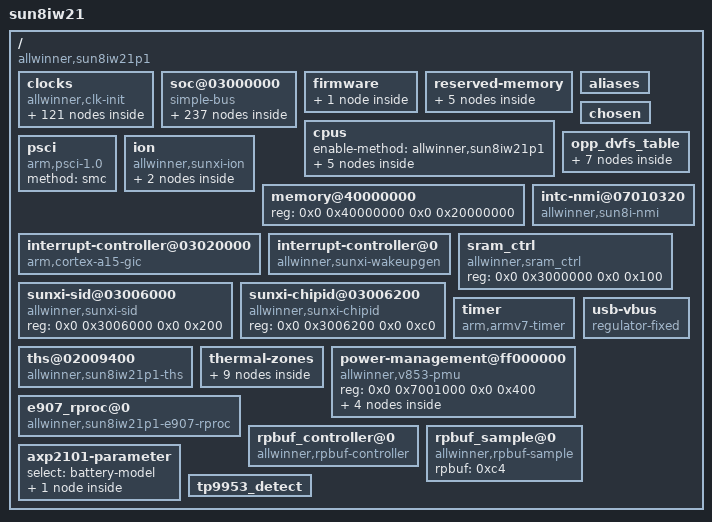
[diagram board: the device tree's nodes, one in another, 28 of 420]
/dts-v1/;

/ {
	model = "sun8iw21";
	compatible = "allwinner,sun8iw21p1";
	interrupt-parent = <0x1>;
	#address-cells = <0x2>;
	#size-cells = <0x2>;

	clocks {
		compatible = "allwinner,clk-init";
		device_type = "clocks";
		#address-cells = <0x2>;
		#size-cells = <0x2>;
		ranges;
		reg = <0x0 0x2001000 0x0 0x1000 0x0 0x7010000 0x0 0x400 0x0 0x7090000 0x0 0x400>;

		ext_losc {
			#clock-cells = <0x0>;
			compatible = "allwinner,fixed-clock";
			clock-frequency = <0x8000>;
			clock-output-names = "ext_losc";
		};

		iosc {
			#clock-cells = <0x0>;
			compatible = "allwinner,fixed-clock";
			clock-frequency = <0xf42400>;
			clock-output-names = "iosc";
			linux,phandle = <0x3>;
			phandle = <0x3>;
		};

		hosc {
			#clock-cells = <0x0>;
			compatible = "allwinner,fixed-clock";
			clock-frequency = <0x16e3600>;
			clock-output-names = "hosc";
			linux,phandle = <0xc>;
			phandle = <0xc>;
		};

		hoscdiv32k {
			#clock-cells = <0x0>;
			compatible = "allwinner,fixed-clock";
			clock-frequency = <0x8000>;
			clock-output-names = "hoscdiv32k";
		};

		osc48m {
			#clock-cells = <0x0>;
			compatible = "allwinner,fixed-clock";
			clock-frequency = <0x2dc6c00>;
			clock-output-names = "osc48m";
			linux,phandle = <0xd>;
			phandle = <0xd>;
		};

		pll_cpu {
			#clock-cells = <0x0>;
			compatible = "allwinner,pll-clock";
			lock-mode = "new";
			clock-output-names = "pll_cpu";
			linux,phandle = <0xb3>;
			phandle = <0xb3>;
		};

		pll_ddr0 {
			#clock-cells = <0x0>;
			compatible = "allwinner,pll-clock";
			lock-mode = "new";
			clock-output-names = "pll_ddr0";
		};

		pll_periph0x2 {
			#clock-cells = <0x0>;
			compatible = "allwinner,pll-clock";
			assigned-clock-rates = <0x47868c00>;
			lock-mode = "new";
			clock-output-names = "pll_periph0x2";
			linux,phandle = <0x4>;
			phandle = <0x4>;
		};

		pll_periph0800m {
			#clock-cells = <0x0>;
			compatible = "allwinner,pll-clock";
			assigned-clock-rates = <0x2faf0800>;
			lock-mode = "new";
			clock-output-names = "pll_periph0800m";
		};

		pll_periph0480m {
			#clock-cells = <0x0>;
			compatible = "allwinner,pll-clock";
			lock-mode = "new";
			clock-output-names = "pll_periph0480m";
			linux,phandle = <0x7>;
			phandle = <0x7>;
		};

		pll_video0x4 {
			#clock-cells = <0x0>;
			compatible = "allwinner,pll-clock";
			lock-mode = "new";
			clock-output-names = "pll_video0x4";
			linux,phandle = <0xb>;
			phandle = <0xb>;
		};

		pll_csix4 {
			#clock-cells = <0x0>;
			compatible = "allwinner,pll-clock";
			assigned-clock-rates = <0x46cf7100>;
			lock-mode = "new";
			clock-output-names = "pll_csix4";
			linux,phandle = <0x9b>;
			phandle = <0x9b>;
		};

		pll_audio_div2 {
			#clock-cells = <0x0>;
			compatible = "allwinner,pll-clock";
			assigned-clock-rates = <0x5b8d8000>;
			lock-mode = "new";
			clock-output-names = "pll_audio_div2";
		};

		pll_audio_div5 {
			#clock-cells = <0x0>;
			compatible = "allwinner,pll-clock";
			assigned-clock-rates = <0x249f0000>;
			lock-mode = "new";
			clock-output-names = "pll_audio_div5";
		};

		pll_npux4 {
			#clock-cells = <0x0>;
			compatible = "allwinner,pll-clock";
			lock-mode = "new";
			clock-output-names = "pll_npux4";
			assigned-clock-rates = <0x52f83c00>;
			assigned-clocks = <0x2>;
			linux,phandle = <0x2>;
			phandle = <0x2>;
		};

		iosc32k {
			#clock-cells = <0x0>;
			compatible = "allwinner,fixed-factor-clock";
			clocks = <0x3>;
			clock-mult = <0x1>;
			clock-div = <0x1f4>;
			clock-output-names = "iosc32k";
		};

		pll_periph0600m {
			#clock-cells = <0x0>;
			compatible = "allwinner,fixed-factor-clock";
			clocks = <0x4>;
			clock-mult = <0x1>;
			clock-div = <0x2>;
			clock-output-names = "pll_periph0600m";
			linux,phandle = <0x5>;
			phandle = <0x5>;
		};

		pll_periph0400m {
			#clock-cells = <0x0>;
			compatible = "allwinner,fixed-factor-clock";
			clocks = <0x4>;
			clock-mult = <0x1>;
			clock-div = <0x3>;
			clock-output-names = "pll_periph0400m";
			linux,phandle = <0x6>;
			phandle = <0x6>;
		};

		pll_periph0300m {
			#clock-cells = <0x0>;
			compatible = "allwinner,fixed-factor-clock";
			clocks = <0x5>;
			clock-mult = <0x1>;
			clock-div = <0x2>;
			clock-output-names = "pll_periph0300m";
			linux,phandle = <0x8>;
			phandle = <0x8>;
		};

		pll_periph0200m {
			#clock-cells = <0x0>;
			compatible = "allwinner,fixed-factor-clock";
			clocks = <0x6>;
			clock-mult = <0x1>;
			clock-div = <0x2>;
			clock-output-names = "pll_periph0200m";
		};

		pll_periph0160m {
			#clock-cells = <0x0>;
			compatible = "allwinner,fixed-factor-clock";
			clocks = <0x7>;
			clock-mult = <0x1>;
			clock-div = <0x3>;
			clock-output-names = "pll_periph0160m";
			linux,phandle = <0xa>;
			phandle = <0xa>;
		};

		pll_periph0150m {
			#clock-cells = <0x0>;
			compatible = "allwinner,fixed-factor-clock";
			clocks = <0x8>;
			clock-mult = <0x1>;
			clock-div = <0x2>;
			clock-output-names = "pll_periph0150m";
			linux,phandle = <0x9>;
			phandle = <0x9>;
		};

		pll_periph0150m_div6 {
			#clock-cells = <0x0>;
			compatible = "allwinner,fixed-factor-clock";
			clocks = <0x9>;
			clock-mult = <0x1>;
			clock-div = <0x6>;
			clock-output-names = "pll_periph0150m_div6";
		};

		pll_periph0160m_div10 {
			#clock-cells = <0x0>;
			compatible = "allwinner,fixed-factor-clock";
			clocks = <0xa>;
			clock-mult = <0x1>;
			clock-div = <0xa>;
			clock-output-names = "pll_periph0160m_div10";
		};

		pll_video0x2 {
			#clock-cells = <0x0>;
			compatible = "allwinner,fixed-factor-clock";
			clocks = <0xb>;
			clock-mult = <0x1>;
			clock-div = <0x2>;
			clock-output-names = "pll_video0x2";
		};

		pll_video0 {
			#clock-cells = <0x0>;
			compatible = "allwinner,fixed-factor-clock";
			clocks = <0xb>;
			clock-mult = <0x1>;
			clock-div = <0x4>;
			clock-output-names = "pll_video0";
			linux,phandle = <0x28>;
			phandle = <0x28>;
		};

		pll_npux2 {
			#clock-cells = <0x0>;
			compatible = "allwinner,fixed-factor-clock";
			clocks = <0x2>;
			clock-mult = <0x1>;
			clock-div = <0x2>;
			clock-output-names = "pll_npux2";
		};

		pll_npu {
			#clock-cells = <0x0>;
			compatible = "allwinner,fixed-factor-clock";
			clocks = <0x2>;
			clock-mult = <0x1>;
			clock-div = <0x4>;
			clock-output-names = "pll_npu";
		};

		hoscd2 {
			#clock-cells = <0x0>;
			compatible = "allwinner,fixed-factor-clock";
			clocks = <0xc>;
			clock-mult = <0x1>;
			clock-div = <0x2>;
			clock-output-names = "hoscd2";
		};

		osc48md4 {
			#clock-cells = <0x0>;
			compatible = "allwinner,fixed-factor-clock";
			clocks = <0xd>;
			clock-mult = <0x1>;
			clock-div = <0x4>;
			clock-output-names = "osc48md4";
		};

		sdramd4 {
			#clock-cells = <0x0>;
			compatible = "allwinner,fixed-factor-clock";
			clocks = <0xe>;
			clock-mult = <0x1>;
			clock-div = <0x4>;
			clock-output-names = "sdramd4";
		};

		cpu {
			#clock-cells = <0x0>;
			compatible = "allwinner,cpu-clock";
			clock-output-names = "cpu";
		};

		axi {
			#clock-cells = <0x0>;
			compatible = "allwinner,periph-clock";
			clock-output-names = "axi";
		};

		cpuapb {
			#clock-cells = <0x0>;
			compatible = "allwinner,periph-clock";
			clock-output-names = "cpuapb";
		};

		ahb {
			#clock-cells = <0x0>;
			compatible = "allwinner,periph-clock";
			clock-output-names = "ahb";
		};

		apb0 {
			#clock-cells = <0x0>;
			compatible = "allwinner,periph-clock";
			clock-output-names = "apb0";
			linux,phandle = <0x14>;
			phandle = <0x14>;
		};

		apb1 {
			#clock-cells = <0x0>;
			compatible = "allwinner,periph-clock";
			clock-output-names = "apb1";
		};

		de {
			#clock-cells = <0x0>;
			compatible = "allwinner,periph-clock";
			assigned-clock-rates = <0x11e1a300>;
			clock-output-names = "de";
			assigned-clock-parents = <0x8>;
			assigned-clocks = <0xf>;
			linux,phandle = <0xf>;
			phandle = <0xf>;
		};

		g2d {
			#clock-cells = <0x0>;
			compatible = "allwinner,periph-clock";
			assigned-clock-rates = <0x11e1a300>;
			clock-output-names = "g2d";
			assigned-clock-parents = <0x8>;
			assigned-clocks = <0x10>;
			linux,phandle = <0x10>;
			phandle = <0x10>;
		};

		ce {
			#clock-cells = <0x0>;
			compatible = "allwinner,periph-clock";
			clock-output-names = "ce";
			linux,phandle = <0x2b>;
			phandle = <0x2b>;
		};

		ve {
			#clock-cells = <0x0>;
			compatible = "allwinner,periph-clock";
			clock-output-names = "ve";
			linux,phandle = <0x29>;
			phandle = <0x29>;
		};

		npu {
			#clock-cells = <0x0>;
			compatible = "allwinner,periph-clock";
			clock-output-names = "npu";
			assigned-clock-parents = <0x2>;
			assigned-clock-rates = <0x14be0f00>;
			assigned-clocks = <0x11>;
			linux,phandle = <0x11>;
			phandle = <0x11>;
		};

		dma {
			#clock-cells = <0x0>;
			compatible = "allwinner,periph-clock";
			clock-output-names = "dma";
		};

		msgbox0 {
			#clock-cells = <0x0>;
			compatible = "allwinner,periph-clock";
			clock-output-names = "msgbox0";
			linux,phandle = <0x3a>;
			phandle = <0x3a>;
		};

		msgbox1 {
			#clock-cells = <0x0>;
			compatible = "allwinner,periph-clock";
			clock-output-names = "msgbox1";
		};

		spinlock {
			#clock-cells = <0x0>;
			compatible = "allwinner,periph-clock";
			clock-output-names = "spinlock";
			linux,phandle = <0x16>;
			phandle = <0x16>;
		};

		hstimer {
			#clock-cells = <0x0>;
			compatible = "allwinner,periph-clock";
			clock-output-names = "hstimer";
		};

		avs {
			#clock-cells = <0x0>;
			compatible = "allwinner,periph-clock";
			clock-output-names = "avs";
		};

		dbgsys {
			#clock-cells = <0x0>;
			compatible = "allwinner,periph-clock";
			clock-output-names = "dbgsys";
		};

		pwm {
			#clock-cells = <0x0>;
			compatible = "allwinner,periph-clock";
			clock-output-names = "pwm";
			linux,phandle = <0x57>;
			phandle = <0x57>;
		};

		iommu {
			#clock-cells = <0x0>;
			compatible = "allwinner,periph-clock";
			clock-output-names = "iommu";
			linux,phandle = <0x2a>;
			phandle = <0x2a>;
		};

		sdram {
			#clock-cells = <0x0>;
			compatible = "allwinner,periph-clock";
			clock-output-names = "sdram";
			linux,phandle = <0xe>;
			phandle = <0xe>;
		};

		sdmmc0_mod {
			#clock-cells = <0x0>;
			compatible = "allwinner,periph-clock";
			clock-output-names = "sdmmc0_mod";
			linux,phandle = <0x6e>;
			phandle = <0x6e>;
		};

		sdmmc0_bus {
			#clock-cells = <0x0>;
			compatible = "allwinner,periph-clock";
			clock-output-names = "sdmmc0_bus";
			linux,phandle = <0x6f>;
			phandle = <0x6f>;
		};

		sdmmc0_rst {
			#clock-cells = <0x0>;
			compatible = "allwinner,periph-clock";
			clock-output-names = "sdmmc0_rst";
			linux,phandle = <0x70>;
			phandle = <0x70>;
		};

		sdmmc1_mod {
			#clock-cells = <0x0>;
			compatible = "allwinner,periph-clock";
			clock-output-names = "sdmmc1_mod";
			linux,phandle = <0x74>;
			phandle = <0x74>;
		};

		sdmmc1_bus {
			#clock-cells = <0x0>;
			compatible = "allwinner,periph-clock";
			clock-output-names = "sdmmc1_bus";
			linux,phandle = <0x75>;
			phandle = <0x75>;
		};

		sdmmc1_rst {
			#clock-cells = <0x0>;
			compatible = "allwinner,periph-clock";
			clock-output-names = "sdmmc1_rst";
			linux,phandle = <0x76>;
			phandle = <0x76>;
		};

		sdmmc2_mod {
			#clock-cells = <0x0>;
			compatible = "allwinner,periph-clock";
			clock-output-names = "sdmmc2_mod";
			linux,phandle = <0x68>;
			phandle = <0x68>;
		};

		sdmmc2_bus {
			#clock-cells = <0x0>;
			compatible = "allwinner,periph-clock";
			clock-output-names = "sdmmc2_bus";
			linux,phandle = <0x69>;
			phandle = <0x69>;
		};

		sdmmc2_rst {
			#clock-cells = <0x0>;
			compatible = "allwinner,periph-clock";
			clock-output-names = "sdmmc2_rst";
			linux,phandle = <0x6a>;
			phandle = <0x6a>;
		};

		uart0 {
			#clock-cells = <0x0>;
			compatible = "allwinner,periph-clock";
			clock-output-names = "uart0";
			linux,phandle = <0x17>;
			phandle = <0x17>;
		};

		uart1 {
			#clock-cells = <0x0>;
			compatible = "allwinner,periph-clock";
			clock-output-names = "uart1";
			linux,phandle = <0x1b>;
			phandle = <0x1b>;
		};

		uart2 {
			#clock-cells = <0x0>;
			compatible = "allwinner,periph-clock";
			clock-output-names = "uart2";
			linux,phandle = <0x1e>;
			phandle = <0x1e>;
		};

		uart3 {
			#clock-cells = <0x0>;
			compatible = "allwinner,periph-clock";
			clock-output-names = "uart3";
			linux,phandle = <0x21>;
			phandle = <0x21>;
		};

		twi0 {
			#clock-cells = <0x0>;
			compatible = "allwinner,periph-clock";
			clock-output-names = "twi0";
			linux,phandle = <0x3b>;
			phandle = <0x3b>;
		};

		twi1 {
			#clock-cells = <0x0>;
			compatible = "allwinner,periph-clock";
			clock-output-names = "twi1";
			linux,phandle = <0x3e>;
			phandle = <0x3e>;
		};

		twi2 {
			#clock-cells = <0x0>;
			compatible = "allwinner,periph-clock";
			clock-output-names = "twi2";
			linux,phandle = <0x41>;
			phandle = <0x41>;
		};

		twi3 {
			#clock-cells = <0x0>;
			compatible = "allwinner,periph-clock";
			clock-output-names = "twi3";
			linux,phandle = <0x44>;
			phandle = <0x44>;
		};

		twi4 {
			#clock-cells = <0x0>;
			compatible = "allwinner,periph-clock";
			clock-output-names = "twi4";
			linux,phandle = <0x48>;
			phandle = <0x48>;
		};

		spi0 {
			#clock-cells = <0x0>;
			compatible = "allwinner,periph-clock";
			clock-output-names = "spi0";
			linux,phandle = <0x2c>;
			phandle = <0x2c>;
		};

		spi1 {
			#clock-cells = <0x0>;
			compatible = "allwinner,periph-clock";
			clock-output-names = "spi1";
			linux,phandle = <0x31>;
			phandle = <0x31>;
		};

		spi2 {
			#clock-cells = <0x0>;
			compatible = "allwinner,periph-clock";
			clock-output-names = "spi2";
		};

		spi3 {
			#clock-cells = <0x0>;
			compatible = "allwinner,periph-clock";
			clock-output-names = "spi3";
			linux,phandle = <0x35>;
			phandle = <0x35>;
		};

		spif {
			#clock-cells = <0x0>;
			compatible = "allwinner,periph-clock";
			clock-output-names = "spif";
			linux,phandle = <0x36>;
			phandle = <0x36>;
		};

		gmac_25m {
			#clock-cells = <0x0>;
			compatible = "allwinner,periph-clock";
			clock-output-names = "gmac_25m";
			linux,phandle = <0x97>;
			phandle = <0x97>;
		};

		gmac {
			#clock-cells = <0x0>;
			compatible = "allwinner,periph-clock";
			clock-output-names = "gmac";
			linux,phandle = <0x96>;
			phandle = <0x96>;
		};

		gpadc {
			#clock-cells = <0x0>;
			assigned-clock-rates = <0x16e3600>;
			compatible = "allwinner,periph-clock";
			clock-output-names = "gpadc";
			assigned-clocks = <0x12>;
			linux,phandle = <0x12>;
			phandle = <0x12>;
		};

		ths {
			#clock-cells = <0x0>;
			compatible = "allwinner,periph-clock";
			clock-output-names = "ths";
			linux,phandle = <0xb9>;
			phandle = <0xb9>;
		};

		pll_audiox4 {
			#clock-cells = <0x0>;
			compatible = "allwinner,periph-clock";
			clock-output-names = "pll_audiox4";
		};

		pll_audio {
			#clock-cells = <0x0>;
			compatible = "allwinner,periph-clock";
			clock-output-names = "pll_audio";
			linux,phandle = <0x84>;
			phandle = <0x84>;
		};

		i2s0 {
			#clock-cells = <0x0>;
			compatible = "allwinner,periph-clock";
			clock-output-names = "i2s0";
			linux,phandle = <0x8d>;
			phandle = <0x8d>;
		};

		i2s1 {
			#clock-cells = <0x0>;
			compatible = "allwinner,periph-clock";
			clock-output-names = "i2s1";
			linux,phandle = <0x90>;
			phandle = <0x90>;
		};

		dmic {
			#clock-cells = <0x0>;
			compatible = "allwinner,periph-clock";
			clock-output-names = "dmic";
			linux,phandle = <0x89>;
			phandle = <0x89>;
		};

		codec_dac {
			#clock-cells = <0x0>;
			compatible = "allwinner,periph-clock";
			clock-output-names = "codec_dac";
			linux,phandle = <0x85>;
			phandle = <0x85>;
		};

		codec_adc {
			#clock-cells = <0x0>;
			compatible = "allwinner,periph-clock";
			clock-output-names = "codec_adc";
			linux,phandle = <0x86>;
			phandle = <0x86>;
		};

		usbphy0 {
			#clock-cells = <0x0>;
			compatible = "allwinner,periph-clock";
			clock-output-names = "usbphy0";
			linux,phandle = <0x7e>;
			phandle = <0x7e>;
		};

		usbohci0 {
			#clock-cells = <0x0>;
			compatible = "allwinner,periph-clock";
			clock-output-names = "usbohci0";
			linux,phandle = <0x82>;
			phandle = <0x82>;
		};

		usbohci0_12m {
			#clock-cells = <0x0>;
			compatible = "allwinner,periph-clock";
			clock-output-names = "usbohci0_12m";
			linux,phandle = <0x83>;
			phandle = <0x83>;
		};

		usbehci0 {
			#clock-cells = <0x0>;
			compatible = "allwinner,periph-clock";
			clock-output-names = "usbehci0";
			linux,phandle = <0x80>;
			phandle = <0x80>;
		};

		usbotg {
			#clock-cells = <0x0>;
			compatible = "allwinner,periph-clock";
			clock-output-names = "usbotg";
			linux,phandle = <0x7f>;
			phandle = <0x7f>;
		};

		dpss_top {
			#clock-cells = <0x0>;
			compatible = "allwinner,periph-clock";
			clock-output-names = "dpss_top";
			linux,phandle = <0x79>;
			phandle = <0x79>;
		};

		mipi_dsi {
			#clock-cells = <0x0>;
			compatible = "allwinner,periph-clock";
			assigned-clocks = <0x13>;
			assigned-clock-parents = <0x9>;
			clock-output-names = "mipi_dsi";
			linux,phandle = <0x13>;
			phandle = <0x13>;
		};

		tcon_lcd {
			#clock-cells = <0x0>;
			compatible = "allwinner,periph-clock";
			clock-output-names = "tcon_lcd";
			linux,phandle = <0x7a>;
			phandle = <0x7a>;
		};

		csi_top {
			#clock-cells = <0x0>;
			compatible = "allwinner,periph-clock";
			clock-output-names = "csi_top";
			linux,phandle = <0x9a>;
			phandle = <0x9a>;
		};

		csi_master0 {
			#clock-cells = <0x0>;
			compatible = "allwinner,periph-clock";
			clock-output-names = "csi_master0";
			linux,phandle = <0x9c>;
			phandle = <0x9c>;
		};

		csi_master1 {
			#clock-cells = <0x0>;
			compatible = "allwinner,periph-clock";
			clock-output-names = "csi_master1";
			linux,phandle = <0x9d>;
			phandle = <0x9d>;
		};

		csi_master2 {
			#clock-cells = <0x0>;
			compatible = "allwinner,periph-clock";
			clock-output-names = "csi_master2";
			linux,phandle = <0x9e>;
			phandle = <0x9e>;
		};

		isp {
			#clock-cells = <0x0>;
			compatible = "allwinner,periph-clock";
			clock-output-names = "isp";
			linux,phandle = <0x9f>;
			phandle = <0x9f>;
		};

		wiegand {
			#clock-cells = <0x0>;
			compatible = "allwinner,periph-clock";
			clock-output-names = "wiegand";
			linux,phandle = <0x93>;
			phandle = <0x93>;
		};

		e907 {
			#clock-cells = <0x0>;
			compatible = "allwinner,periph-clock";
			clock-output-names = "e907";
		};

		e907_axi {
			#clock-cells = <0x0>;
			compatible = "allwinner,periph-clock";
			clock-output-names = "e907_axi";
		};

		fanout_25m {
			#clock-cells = <0x0>;
			compatible = "allwinner,periph-clock";
			clock-output-names = "fanout_25m";
		};

		fanout_16m {
			#clock-cells = <0x0>;
			compatible = "allwinner,periph-clock";
			clock-output-names = "fanout_16m";
		};

		fanout_12m {
			#clock-cells = <0x0>;
			compatible = "allwinner,periph-clock";
			clock-output-names = "fanout_12m";
		};

		fanout_24m {
			#clock-cells = <0x0>;
			compatible = "allwinner,periph-clock";
			clock-output-names = "fanout_24m";
		};

		fanout_27m {
			#clock-cells = <0x0>;
			compatible = "allwinner,periph-clock";
			clock-output-names = "fanout_27m";
		};

		fanout_pclk {
			#clock-cells = <0x0>;
			compatible = "allwinner,periph-clock";
			clock-output-names = "fanout_pclk";
		};

		fanout0 {
			#clock-cells = <0x0>;
			compatible = "allwinner,periph-clock";
			clock-output-names = "fanout0";
			linux,phandle = <0xb2>;
			phandle = <0xb2>;
		};

		fanout1 {
			#clock-cells = <0x0>;
			compatible = "allwinner,periph-clock";
			clock-output-names = "fanout1";
		};

		fanout2 {
			#clock-cells = <0x0>;
			compatible = "allwinner,periph-clock";
			clock-output-names = "fanout2";
		};

		cpurahbs {
			#clock-cells = <0x0>;
			compatible = "allwinner,periph-cpus-clock";
			clock-output-names = "cpurahbs";
		};

		cpurapbs0 {
			#clock-cells = <0x0>;
			compatible = "allwinner,periph-cpus-clock";
			clock-output-names = "cpurapbs0";
		};

		cpurtwd {
			#clock-cells = <0x0>;
			compatible = "allwinner,periph-cpus-clock";
			clock-output-names = "cpurtwd";
		};

		cpurppu {
			#clock-cells = <0x0>;
			compatible = "allwinner,periph-cpus-clock";
			clock-output-names = "cpurppu";
			linux,phandle = <0xbe>;
			phandle = <0xbe>;
		};

		cpurrtc {
			#clock-cells = <0x0>;
			compatible = "allwinner,periph-cpus-clock";
			clock-output-names = "cpurrtc";
		};

		cpurcpus {
			#clock-cells = <0x0>;
			compatible = "allwinner,periph-cpus-clock";
			clock-output-names = "cpurcpus";
		};

		losc {
			#clock-cells = <0x0>;
			compatible = "allwinner,periph-rtc-clock";
			clock-output-names = "losc";
			linux,phandle = <0x15>;
			phandle = <0x15>;
		};

		losc_out {
			#clock-cells = <0x0>;
			compatible = "allwinner,periph-rtc-clock";
			clock-output-names = "losc_out";
		};

		hosc32k {
			#clock-cells = <0x0>;
			compatible = "allwinner,periph-rtc-clock";
			clock-output-names = "hosc32k";
		};

		rtc_spi {
			#clock-cells = <0x0>;
			compatible = "allwinner,periph-rtc-clock";
			clock-output-names = "rtc_spi";
		};
	};

	soc@03000000 {
		compatible = "simple-bus";
		#address-cells = <0x2>;
		#size-cells = <0x2>;
		ranges;
		device_type = "soc";

		pinctrl@07022000 {
			compatible = "allwinner,sun8iw21p1-r-pinctrl";
			reg = <0x0 0x7022000 0x0 0x400>;
			interrupts = <0x0 0x6a 0x4>;
			device_type = "r_pio";
			gpio-controller;
			interrupt-controller;
			#interrupt-cells = <0x3>;
			#size-cells = <0x0>;
		};

		pinctrl@02000000 {
			compatible = "allwinner,sun8iw21p1-pinctrl";
			reg = <0x0 0x2000000 0x0 0x400>;
			interrupts = <0x0 0x43 0x4 0x0 0x47 0x4 0x0 0x49 0x4 0x0 0x4b 0x4 0x0 0x4d 0x4 0x0 0x4f 0x4 0x0 0x51 0x4 0x0 0x53 0x4>;
			device_type = "pio";
			clocks = <0x14>;
			gpio-controller;
			interrupt-controller;
			#interrupt-cells = <0x3>;
			#size-cells = <0x0>;
			#gpio-cells = <0x6>;
			input-debounce = <0x0 0x0 0x0 0x1 0x0 0x0 0x0>;
			linux,phandle = <0x26>;
			phandle = <0x26>;

			uart0@0 {
				allwinner,pins = "PH9", "PH10";
				allwinner,function = "uart0";
				allwinner,muxsel = <0x5>;
				allwinner,drive = <0x1>;
				allwinner,pull = <0x1>;
				linux,phandle = <0x18>;
				phandle = <0x18>;
			};

			uart0@1 {
				allwinner,pins = "PH9", "PH10";
				allwinner,function = "gpio_in";
				allwinner,muxsel = <0x0>;
				linux,phandle = <0x19>;
				phandle = <0x19>;
			};

			test_pins@0 {
				allwinner,pins = "PA0", "PA1";
				allwinner,function = "test";
				allwinner,muxsel = <0x5>;
				allwinner,drive = <0x1>;
				allwinner,pull = <0x1>;
				linux,phandle = <0x27>;
				phandle = <0x27>;
			};

			twi0@0 {
				allwinner,pins = "PE16", "PE17";
				allwinner,pname = "twi0_scl", "twi0_sda";
				allwinner,function = "twi0";
				allwinner,muxsel = <0x2>;
				allwinner,drive = <0x0>;
				allwinner,pull = <0x1>;
				linux,phandle = <0x3c>;
				phandle = <0x3c>;
			};

			twi0@1 {
				allwinner,pins = "PE16", "PE17";
				allwinner,function = "io_disabled";
				allwinner,muxsel = <0xf>;
				allwinner,drive = <0x0>;
				allwinner,pull = <0x0>;
				linux,phandle = <0x3d>;
				phandle = <0x3d>;
			};

			twi1@0 {
				allwinner,pins = "PA14", "PA15";
				allwinner,pname = "twi1_scl", "twi1_sda";
				allwinner,function = "twi1";
				allwinner,muxsel = <0x4>;
				allwinner,drive = <0x0>;
				allwinner,pull = <0x1>;
				linux,phandle = <0x3f>;
				phandle = <0x3f>;
			};

			twi1@1 {
				allwinner,pins = "PA14", "PA15";
				allwinner,function = "io_disabled";
				allwinner,muxsel = <0xf>;
				allwinner,drive = <0x0>;
				allwinner,pull = <0x0>;
				linux,phandle = <0x40>;
				phandle = <0x40>;
			};

			sdc0@0 {
				allwinner,pins = "PF0", "PF1", "PF2", "PF3", "PF4", "PF5";
				allwinner,function = "sdc0";
				allwinner,muxsel = <0x2>;
				allwinner,drive = <0x3>;
				allwinner,pull = <0x1>;
				linux,phandle = <0x71>;
				phandle = <0x71>;
			};

			sdc0@1 {
				allwinner,pins = "PF0", "PF1", "PF2", "PF3", "PF4", "PF5";
				allwinner,function = "io_disabled";
				allwinner,muxsel = <0xf>;
				allwinner,drive = <0x1>;
				allwinner,pull = <0x1>;
				linux,phandle = <0x72>;
				phandle = <0x72>;
			};

			sdc0@2 {
				allwinner,pins = "PF0", "PF1", "PF2", "PF3", "PF4", "PF5";
				allwinner,function = "uart0_jtag";
				allwinner,muxsel = <0x3>;
				allwinner,drive = <0x1>;
				allwinner,pull = <0x1>;
				linux,phandle = <0x73>;
				phandle = <0x73>;
			};

			sdc1@0 {
				allwinner,pins = "PG0", "PG1", "PG2", "PG3", "PG4", "PG5";
				allwinner,function = "sdc1";
				allwinner,muxsel = <0x2>;
				allwinner,drive = <0x3>;
				allwinner,pull = <0x1>;
				linux,phandle = <0x77>;
				phandle = <0x77>;
			};

			sdc1@1 {
				allwinner,pins = "PG0", "PG1", "PG2", "PG3", "PG4", "PG5";
				allwinner,function = "io_disabled";
				allwinner,muxsel = <0xf>;
				allwinner,drive = <0x1>;
				allwinner,pull = <0x1>;
				linux,phandle = <0x78>;
				phandle = <0x78>;
			};

			sdc2@0 {
				allwinner,pins = "PC1", "PC4", "PC5", "PC6", "PC7", "PC8", "PC9", "PC11", "PC2", "PC3", "PC0";
				allwinner,function = "sdc2";
				allwinner,muxsel = <0x3>;
				allwinner,drive = <0x2>;
				allwinner,pull = <0x1>;
				linux,phandle = <0x6b>;
				phandle = <0x6b>;
			};

			sdc2@1 {
				allwinner,pins = "PC1", "PC4", "PC5", "PC6", "PC7", "PC8", "PC9", "PC11", "PC2", "PC3", "PC10", "PC0";
				allwinner,function = "io_disabled";
				allwinner,muxsel = <0xf>;
				allwinner,drive = <0x1>;
				allwinner,pull = <0x1>;
				linux,phandle = <0x6d>;
				phandle = <0x6d>;
			};

			sdc2@2 {
				allwinner,pins = "PC10";
				allwinner,function = "sdc2";
				allwinner,muxsel = <0x3>;
				allwinner,drive = <0x2>;
				allwinner,pull = <0x2>;
				linux,phandle = <0x6c>;
				phandle = <0x6c>;
			};

			csi_mclk0@0 {
				allwinner,pins = "PA12";
				allwinner,pname = "mipi_csi_mclk0";
				allwinner,function = "mipi_csi_mclk0";
				allwinner,muxsel = <0x4>;
				allwinner,drive = <0x2>;
				allwinner,pull = <0x0>;
				linux,phandle = <0xa0>;
				phandle = <0xa0>;
			};

			csi_mclk0@1 {
				allwinner,pins = "PA12";
				allwinner,pname = "mipi_csi_mclk0";
				allwinner,function = "io_disabled";
				allwinner,muxsel = <0xf>;
				allwinner,drive = <0x2>;
				allwinner,pull = <0x0>;
				linux,phandle = <0xa1>;
				phandle = <0xa1>;
			};

			mipia@0 {
				allwinner,pins = "PA0", "PA1", "PA2", "PA3", "PA4", "PA5";
				allwinner,pname = "mipia_ck0p", "mipia_ck0n", "mipia_d1n", "mipia_d1p", "mipia_d0p", "mipia_d0n";
				allwinner,function = "mipia_rx";
				allwinner,muxsel = <0x2>;
				allwinner,drive = <0x1>;
				allwinner,pull = <0x0>;
				linux,phandle = <0xa8>;
				phandle = <0xa8>;
			};

			mipia@1 {
				allwinner,pins = "PA0", "PA1", "PA2", "PA3", "PA4", "PA5";
				allwinner,pname = "mipia_ck0p", "mipia_ck0n", "mipia_d1n", "mipia_d1p", "mipia_d0p", "mipia_d0n";
				allwinner,function = "io_disabled";
				allwinner,muxsel = <0xf>;
				allwinner,drive = <0x1>;
				allwinner,pull = <0x0>;
				linux,phandle = <0xa9>;
				phandle = <0xa9>;
			};

			csi_mclk1@0 {
				allwinner,pins = "PA13";
				allwinner,pname = "mipi_csi_mclk1";
				allwinner,function = "mipi_csi_mclk1";
				allwinner,muxsel = <0x4>;
				allwinner,drive = <0x2>;
				allwinner,pull = <0x0>;
				linux,phandle = <0xa2>;
				phandle = <0xa2>;
			};

			csi_mclk1@1 {
				allwinner,pins = "PA13";
				allwinner,pname = "mipi_csi_mclk1";
				allwinner,function = "io_disabled";
				allwinner,muxsel = <0xf>;
				allwinner,drive = <0x2>;
				allwinner,pull = <0x0>;
				linux,phandle = <0xa3>;
				phandle = <0xa3>;
			};

			mipib@0 {
				allwinner,pins = "PA6", "PA7", "PA8", "PA9", "PA10", "PA11";
				allwinner,pname = "mipib_d0n", "mipib_d0p", "mipib_d1n", "mipib_d1p", "mipib_ck0n", "mipib_ck0p";
				allwinner,function = "mipib_rx";
				allwinner,muxsel = <0x2>;
				allwinner,drive = <0x1>;
				allwinner,pull = <0x0>;
				linux,phandle = <0xac>;
				phandle = <0xac>;
			};

			mipib@1 {
				allwinner,pins = "PA6", "PA7", "PA8", "PA9", "PA10", "PA11";
				allwinner,pname = "mipib_d0n", "mipib_d0p", "mipib_d1n", "mipib_d1p", "mipib_ck0n", "mipib_ck0p";
				allwinner,function = "io_disabled";
				allwinner,muxsel = <0xf>;
				allwinner,drive = <0x1>;
				allwinner,pull = <0x0>;
				linux,phandle = <0xad>;
				phandle = <0xad>;
			};

			mipib_4lane@0 {
				allwinner,pins = "PA6", "PA7", "PA8", "PA9";
				allwinner,pname = "mipib_d0n", "mipib_d0p", "mipib_d1n", "mipib_d1p";
				allwinner,function = "mipib_rx";
				allwinner,muxsel = <0x2>;
				allwinner,drive = <0x1>;
				allwinner,pull = <0x0>;
				linux,phandle = <0xaa>;
				phandle = <0xaa>;
			};

			mipib_4lane@1 {
				allwinner,pins = "PA6", "PA7", "PA8", "PA9";
				allwinner,pname = "mipib_d0n", "mipib_d0p", "mipib_d1n", "mipib_d1p";
				allwinner,function = "io_disabled";
				allwinner,muxsel = <0xf>;
				allwinner,drive = <0x1>;
				allwinner,pull = <0x0>;
				linux,phandle = <0xab>;
				phandle = <0xab>;
			};

			csi_mclk2@0 {
				allwinner,pins = "PE1";
				allwinner,pname = "ncsi_mclk";
				allwinner,function = "ncsi_mclk";
				allwinner,muxsel = <0x2>;
				allwinner,drive = <0x2>;
				allwinner,pull = <0x0>;
				linux,phandle = <0xa4>;
				phandle = <0xa4>;
			};

			csi_mclk2@1 {
				allwinner,pins = "PE1";
				allwinner,pname = "ncsi_mclk";
				allwinner,function = "io_disabled";
				allwinner,muxsel = <0xf>;
				allwinner,drive = <0x2>;
				allwinner,pull = <0x0>;
				linux,phandle = <0xa5>;
				phandle = <0xa5>;
			};

			ncsi@0 {
				allwinner,pins = "PE0", "PE2", "PE3", "PE4", "PE5", "PE6", "PE7", "PE8", "PE9", "PE10", "PE11", "PE12", "PE13", "PE14", "PE15";
				allwinner,pname = "ncsi_pck", "ncsi_hsync", "ncsi_vsync", "ncsi_d0", "ncsi_d1", "ncsi_d2", "ncsi_d3", "ncsi_d4", "ncsi_d5", "ncsi_d6", "ncsi_d7", "ncsi_d8", "ncsi_d9", "ncsi_d10", "ncsi_d11";
				allwinner,function = "ncsi";
				allwinner,muxsel = <0x2>;
				allwinner,drive = <0x1>;
				allwinner,pull = <0x0>;
				linux,phandle = <0xa6>;
				phandle = <0xa6>;
			};

			ncsi@1 {
				allwinner,pins = "PE0", "PE2", "PE3", "PE4", "PE5", "PE6", "PE7", "PE8", "PE9", "PE10", "PE11", "PE12", "PE13", "PE14", "PE15";
				allwinner,pname = "ncsi_pck", "ncsi_hsync", "ncsi_vsync", "ncsi_d0", "ncsi_d1", "ncsi_d2", "ncsi_d3", "ncsi_d4", "ncsi_d5", "ncsi_d6", "ncsi_d7", "ncsi_d8", "ncsi_d9", "ncsi_d10", "ncsi_d11";
				allwinner,function = "io_disabled";
				allwinner,muxsel = <0xf>;
				allwinner,drive = <0x1>;
				allwinner,pull = <0x0>;
				linux,phandle = <0xa7>;
				phandle = <0xa7>;
			};

			ncsi_pa@0 {
				allwinner,pins = "PA21", "PA12", "PA13", "PA14", "PA15", "PA16", "PA17", "PA18", "PA19";
				allwinner,pname = "ncsi_pck", "ncsi_d0", "ncsi_d1", "ncsi_d2", "ncsi_d3", "ncsi_d4", "ncsi_d5", "ncsi_d6", "ncsi_d7";
				allwinner,function = "ncsi";
				allwinner,muxsel = <0x3>;
				allwinner,drive = <0x1>;
				allwinner,pull = <0x0>;
			};

			ncsi_pa@1 {
				allwinner,pins = "PA21", "PA12", "PA13", "PA14", "PA15", "PA16", "PA17", "PA18", "PA19";
				allwinner,pname = "ncsi_pck", "ncsi_d0", "ncsi_d1", "ncsi_d2", "ncsi_d3", "ncsi_d4", "ncsi_d5", "ncsi_d6", "ncsi_d7";
				allwinner,function = "io_disabled";
				allwinner,muxsel = <0xf>;
				allwinner,drive = <0x1>;
				allwinner,pull = <0x0>;
			};

			dsi4lane@0 {
				allwinner,pins = "PD1", "PD2", "PD3", "PD4", "PD5", "PD6", "PD7", "PD9", "PD10", "PD11";
				allwinner,pname = "PD1", "PD2", "PD3", "PD4", "PD5", "PD6", "PD7", "PD9", "PD10", "PD11";
				allwinner,function = "dsi";
				allwinner,muxsel = <0x5>;
				allwinner,drive = <0x3>;
				allwinner,pull = <0x0>;
				linux,phandle = <0x7b>;
				phandle = <0x7b>;
			};

			dsi4lane@1 {
				allwinner,pins = "PD1", "PD2", "PD3", "PD4", "PD5", "PD6", "PD7", "PD9", "PD10", "PD11";
				allwinner,pname = "PD1", "PD2", "PD3", "PD4", "PD5", "PD6", "PD7", "PD9", "PD10", "DP11";
				allwinner,function = "io_disabled";
				allwinner,muxsel = <0xf>;
				allwinner,drive = <0x1>;
				allwinner,pull = <0x0>;
				linux,phandle = <0x7c>;
				phandle = <0x7c>;
			};

			wlan@0 {
				allwinner,pins = "PG6";
				allwinner,function = "fanout0";
				allwinner,muxsel = <0x3>;
				linux,phandle = <0xb1>;
				phandle = <0xb1>;
			};

			uart1@0 {
				allwinner,pins = "PG6", "PG7";
				allwinner,function = "uart1";
				allwinner,muxsel = <0x4>;
				allwinner,drive = <0x1>;
				allwinner,pull = <0x1>;
				linux,phandle = <0x1c>;
				phandle = <0x1c>;
			};

			uart1@1 {
				allwinner,pins = "PG6", "PG7";
				allwinner,function = "gpio_in";
				allwinner,muxsel = <0x0>;
				linux,phandle = <0x1d>;
				phandle = <0x1d>;
			};

			uart2@0 {
				allwinner,pins = "PE12", "PE13", "PE10", "PE11";
				allwinner,function = "uart2";
				allwinner,muxsel = <0x6>;
				allwinner,drive = <0x1>;
				allwinner,pull = <0x1>;
				linux,phandle = <0x1f>;
				phandle = <0x1f>;
			};

			uart2@1 {
				allwinner,pins = "PE12", "PE13", "PE10", "PE11";
				allwinner,function = "gpio_in";
				allwinner,muxsel = <0x0>;
				linux,phandle = <0x20>;
				phandle = <0x20>;
			};

			uart3@0 {
				allwinner,pins = "PH0", "PH1";
				allwinner,function = "uart3";
				allwinner,muxsel = <0x5>;
				allwinner,drive = <0x1>;
				allwinner,pull = <0x1>;
				linux,phandle = <0x22>;
				phandle = <0x22>;
			};

			uart3@1 {
				allwinner,pins = "PH0", "PH1";
				allwinner,function = "gpio_in";
				allwinner,muxsel = <0x0>;
				linux,phandle = <0x23>;
				phandle = <0x23>;
			};

			spi0@0 {
				allwinner,pins = "PC0", "PC2", "PC3";
				allwinner,pname = "spi0_sclk", "spi0_mosi", "spi0_miso";
				allwinner,function = "spi0";
				allwinner,muxsel = <0x4>;
				allwinner,drive = <0x1>;
				allwinner,pull = <0x0>;
				linux,phandle = <0x2d>;
				phandle = <0x2d>;
			};

			spi0@1 {
				allwinner,pins = "PC1", "PC5", "PC4";
				allwinner,pname = "spi0_cs0", "spi0_hold", "spi0_wp";
				allwinner,function = "spi0";
				allwinner,muxsel = <0x4>;
				allwinner,drive = <0x1>;
				allwinner,pull = <0x1>;
				linux,phandle = <0x2e>;
				phandle = <0x2e>;
			};

			spi0@2 {
				allwinner,pins = "PC0", "PC1", "PC2", "PC3", "PC4", "PC5";
				allwinner,function = "io_disabled";
				allwinner,muxsel = <0xf>;
				allwinner,drive = <0x1>;
				allwinner,pull = <0x0>;
				linux,phandle = <0x2f>;
				phandle = <0x2f>;
			};

			spi1@0 {
				allwinner,pins = "PF31", "PF24", "PF29", "PF26", "PF30";
				allwinner,pname = "spi0_sclk", "spi0_mosi", "spi0_miso", "spi0_hold", "spi0_wp";
				allwinner,function = "spi0";
				allwinner,muxsel = <0x5>;
				allwinner,drive = <0x1>;
				allwinner,pull = <0x0>;
				linux,phandle = <0x32>;
				phandle = <0x32>;
			};

			spi1@1 {
				allwinner,pins = "PF25";
				allwinner,pname = "spi0_cs0";
				allwinner,function = "spi0";
				allwinner,muxsel = <0x5>;
				allwinner,drive = <0x1>;
				allwinner,pull = <0x1>;
				linux,phandle = <0x33>;
				phandle = <0x33>;
			};

			spi1@2 {
				allwinner,pins = "PF24", "PF25", "PF26", "PF29", "PF30", "PF31";
				allwinner,function = "io_disabled";
				allwinner,muxsel = <0xf>;
				allwinner,drive = <0x1>;
				allwinner,pull = <0x0>;
				linux,phandle = <0x34>;
				phandle = <0x34>;
			};

			spif0@0 {
				allwinner,pins = "PF24", "PF29", "PF26", "PF30", "PF31", "PF20", "PF21", "PF22", "PF23";
				allwinner,pname = "spif0_mosi", "spif0_miso", "spif0_hold", "spif0_wp", "spif0_sck", "spif0_dq4", "spif0_dq5", "spif0_dq6", "spif0_dq7", "spif0_dqs";
				allwinner,function = "spif";
				allwinner,muxsel = <0x3>;
				allwinner,drive = <0x1>;
				allwinner,pull = <0x0>;
				linux,phandle = <0x37>;
				phandle = <0x37>;
			};

			spif0@1 {
				allwinner,pins = "PF25";
				allwinner,pname = "spif0_cs0";
				allwinner,function = "spif";
				allwinner,muxsel = <0x3>;
				allwinner,drive = <0x1>;
				allwinner,pull = <0x1>;
				linux,phandle = <0x38>;
				phandle = <0x38>;
			};

			spif0@2 {
				allwinner,pins = "PF24", "PF29", "PF26", "PF30", "PF31", "PF20", "PF21", "PF22", "PF23", "PF25", "PF11";
				allwinner,pname = "spif0_mosi", "spif0_miso", "spif0_hold", "spif0_wp", "spif0_sck", "spif0_dq4", "spif0_dq5", "spif0_dq6", "spif0_dq7", "spif0_cs", "spif0_dqs";
				allwinner,function = "io_disabled";
				allwinner,muxsel = <0xf>;
				allwinner,drive = <0x1>;
				allwinner,pull = <0x0>;
				linux,phandle = <0x39>;
				phandle = <0x39>;
			};

			twi2@0 {
				allwinner,pins = "PH5", "PH6";
				allwinner,pname = "twi2_scl", "twi2_sda";
				allwinner,function = "twi2";
				allwinner,muxsel = <0x4>;
				allwinner,drive = <0x0>;
				allwinner,pull = <0x1>;
				linux,phandle = <0x42>;
				phandle = <0x42>;
			};

			twi2@1 {
				allwinner,pins = "PH5", "PH6";
				allwinner,function = "io_disabled";
				allwinner,muxsel = <0xf>;
				allwinner,drive = <0x0>;
				allwinner,pull = <0x0>;
				linux,phandle = <0x43>;
				phandle = <0x43>;
			};

			twi3@0 {
				allwinner,pins = "PI3", "PI4";
				allwinner,pname = "twi3_scl", "twi3_sda";
				allwinner,function = "twi3";
				allwinner,muxsel = <0x6>;
				allwinner,drive = <0x0>;
				allwinner,pull = <0x1>;
				linux,phandle = <0x45>;
				phandle = <0x45>;
			};

			twi3@1 {
				allwinner,pins = "PI3", "PI4";
				allwinner,function = "io_disabled";
				allwinner,muxsel = <0xf>;
				allwinner,drive = <0x0>;
				allwinner,pull = <0x0>;
				linux,phandle = <0x46>;
				phandle = <0x46>;
			};

			twi4@0 {
				allwinner,pins = "PI1", "PI2";
				allwinner,pname = "twi4_scl", "twi4_sda";
				allwinner,function = "twi4";
				allwinner,muxsel = <0x6>;
				allwinner,drive = <0x0>;
				allwinner,pull = <0x1>;
				linux,phandle = <0x49>;
				phandle = <0x49>;
			};

			twi4@1 {
				allwinner,pins = "PI1", "PI2";
				allwinner,function = "io_disabled";
				allwinner,muxsel = <0xf>;
				allwinner,drive = <0x0>;
				allwinner,pull = <0x0>;
				linux,phandle = <0x4a>;
				phandle = <0x4a>;
			};

			dmic@0 {
				allwinner,pins = "PH0", "PH1", "PH2", "PH3", "PH4";
				allwinner,function = "dmic";
				allwinner,muxsel = <0x6>;
				allwinner,drive = <0x1>;
				allwinner,pull = <0x0>;
				linux,phandle = <0x8a>;
				phandle = <0x8a>;
			};

			dmic_sleep@0 {
				allwinner,pins = "PH0", "PH1", "PH2", "PH3", "PH4";
				allwinner,function = "io_disabled";
				allwinner,muxsel = <0xf>;
				allwinner,drive = <0x1>;
				allwinner,pull = <0x0>;
				linux,phandle = <0x8b>;
				phandle = <0x8b>;
			};

			daudio0@0 {
				allwinner,pins = "PH0", "PH1", "PH2", "PH3", "PH4";
				allwinner,function = "i2s0";
				allwinner,muxsel = <0x3>;
				allwinner,drive = <0x1>;
				allwinner,pull = <0x0>;
			};

			daudio0_sleep@0 {
				allwinner,pins = "PH0", "PH1", "PH2", "PH3", "PH4";
				allwinner,function = "io_disabled";
				allwinner,muxsel = <0xf>;
				allwinner,drive = <0x1>;
				allwinner,pull = <0x0>;
			};

			daudio1@0 {
				allwinner,pins = "PE7", "PE8", "PE9", "PE10", "PE11";
				allwinner,function = "i2s1";
				allwinner,muxsel = <0x7>;
				allwinner,drive = <0x1>;
				allwinner,pull = <0x0>;
			};

			daudio1_sleep@0 {
				allwinner,pins = "PE7", "PE8", "PE9", "PE10", "PE11";
				allwinner,function = "io_disabled";
				allwinner,muxsel = <0xf>;
				allwinner,drive = <0x1>;
				allwinner,pull = <0x0>;
			};

			pwm4@0 {
				pins = "PH11";
				function = "pwm4";
				muxsel = <0x8>;
				drive-strength = <0xa>;
				bias-pull-up;
				linux,phandle = <0x64>;
				phandle = <0x64>;
			};

			pwm4@1 {
				pins = "PH11";
				function = "gpio_in";
				muxsel = <0x0>;
				linux,phandle = <0x65>;
				phandle = <0x65>;
			};

			pwm9@0 {
				pins = "PD22";
				function = "pwm9";
				muxsel = <0x2>;
				drive-strength = <0xa>;
				bias-pull-up;
				linux,phandle = <0x66>;
				phandle = <0x66>;
			};

			pwm9@1 {
				pins = "PD22";
				function = "gpio_in";
				muxsel = <0x0>;
				linux,phandle = <0x67>;
				phandle = <0x67>;
			};

			wiegand@0 {
				pins = "PH13", "PH14";
				function = "wiegand";
				muxsel = <0x7>;
				drive-strength = <0xa>;
				bias-pull-up;
				linux,phandle = <0x94>;
				phandle = <0x94>;
			};

			wiegand@1 {
				pins = "PH13", "PH14";
				function = "io_disabled";
				muxsel = <0xf>;
				linux,phandle = <0x95>;
				phandle = <0x95>;
			};

			gmac0@0 {
				allwinner,pins = "PE0", "PE1", "PE2", "PE3", "PE4", "PE5", "PE6", "PE7", "PE8", "PE9", "PE10", "PE11", "PE12", "PE13", "PE14", "PE15";
				allwinner,function = "rgmii";
				allwinner,drive = <0x1>;
				allwinner,muxsel = <0x3>;
				allwinner,pull = <0x0>;
				linux,phandle = <0x98>;
				phandle = <0x98>;
			};

			gmac0@1 {
				allwinner,pins = "PE0", "PE1", "PE2", "PE3", "PE4", "PE5", "PE6", "PE7", "PE8", "PE9", "PE10", "PE11", "PE12", "PE13", "PE14", "PE15";
				allwinner,function = "gpio_in";
				allwinner,drive = <0x0>;
				allwinner,muxsel = <0x0>;
				allwinner,pull = <0x0>;
				linux,phandle = <0x99>;
				phandle = <0x99>;
			};
		};

		timer@02050000 {
			compatible = "allwinner,sun4i-a10-timer";
			device_type = "soc_timer";
			reg = <0x0 0x2050000 0x0 0x90>;
			interrupts = <0x0 0x3b 0x4>;
			clocks = <0xc 0x15>;
		};

		watchdog@20500a0 {
			compatible = "allwinner,sun8i-wdt";
			reg = <0x0 0x20500a0 0x0 0x20>;
			interrupts = <0x0 0x3f 0x4>;
		};

		dump_reg@20000 {
			compatible = "allwinner,sunxi-dump-reg";
			reg = <0x0 0x20000 0x0 0x4>;
		};

		hwspinlock@3005000 {
			compatible = "allwinner,sunxi-hwspinlock";
			reg = <0x0 0x3005000 0x0 0x1000>;
			#hwlock-cells = <0x1>;
			clocks = <0x16>;
			num-locks = <0x20>;
			status = "okay";
		};

		uart@2500000 {
			compatible = "allwinner,sun8i-uart";
			device_type = "uart0";
			reg = <0x0 0x2500000 0x0 0x400>;
			interrupts = <0x0 0x2 0x4>;
			clocks = <0x17>;
			sunxi,uart-fifosize = <0x40>;
			uart0_port = <0x0>;
			uart0_type = <0x2>;
			status = "okay";
			pinctrl-names = "default", "sleep";
			pinctrl-0 = <0x18>;
			pinctrl-1 = <0x19>;
			uart-supply = <0x1a>;
		};

		uart@2500400 {
			compatible = "allwinner,sun8i-uart";
			device_type = "uart1";
			reg = <0x0 0x2500400 0x0 0x400>;
			interrupts = <0x0 0x3 0x4>;
			clocks = <0x1b>;
			sunxi,uart-fifosize = <0x80>;
			uart1_port = <0x1>;
			uart1_type = <0x4>;
			status = "disabled";
			pinctrl-names = "default", "sleep";
			pinctrl-0 = <0x1c>;
			pinctrl-1 = <0x1d>;
			uart-supply = <0x1a>;
		};

		uart@2500800 {
			compatible = "allwinner,sun8i-uart";
			device_type = "uart2";
			reg = <0x0 0x2500800 0x0 0x400>;
			interrupts = <0x0 0x4 0x4>;
			clocks = <0x1e>;
			sunxi,uart-fifosize = <0x80>;
			uart2_port = <0x2>;
			uart2_type = <0x4>;
			status = "disabled";
			pinctrl-names = "default", "sleep";
			pinctrl-0 = <0x1f>;
			pinctrl-1 = <0x20>;
			uart-supply = <0x1a>;
		};

		uart@2500c00 {
			compatible = "allwinner,sun8i-uart";
			device_type = "uart3";
			reg = <0x0 0x2500c00 0x0 0x400>;
			interrupts = <0x0 0x5 0x4>;
			clocks = <0x21>;
			sunxi,uart-fifosize = <0x80>;
			uart3_port = <0x3>;
			uart3_type = <0x4>;
			status = "okay";
			pinctrl-names = "default", "sleep";
			pinctrl-0 = <0x22>;
			pinctrl-1 = <0x23>;
			uart-supply = <0x1a>;
		};

		npu@03050000 {
			compatible = "allwinner,npu";
			reg = <0x0 0x3050000 0x0 0x1000>;
			device_type = "npu";
			dev_name = "npu";
			interrupts = <0x0 0x41 0x4>;
			clocks = <0x11 0x2>;
			clock-frequency = <0x1e0a6e00>;
			interrupt-names = "npu";
			iommus = <0x24 0x6 0x1>;
			status = "okay";
			power-domains = <0x25 0x1>;
		};

		pinctrl-test@0 {
			compatible = "allwinner,sun8i-pinctrl-test";
			device_type = "pinctrl-test";
			interrupt-parent = <0x26>;
			interrupts = <0x0 0x2 0x4>;
			pinctrl-names = "default";
			pinctrl-0 = <0x27>;
			test-gpios = <0x26 0x0 0x3 0x1 0x2 0x2 0x1>;
			status = "okay";
		};

		rt-media@01c0e000 {
			compatible = "allwinner,rt-media";
		};

		ve@01c0e000 {
			compatible = "allwinner,sunxi-cedar-ve";
			reg = <0x0 0x1c0e000 0x0 0x1000 0x0 0x3000000 0x0 0x10 0x0 0x2001000 0x0 0x800 0x0 0x5830000 0x0 0x1000>;
			interrupts = <0x0 0x42 0x4>;
			clocks = <0x28 0x29>;
			iommus = <0x24 0x0 0x1>;
			power-domains = <0x25 0x2>;
		};

		iommu@02010000 {
			compatible = "allwinner,sunxi-iommu";
			reg = <0x0 0x2010000 0x0 0x400>;
			interrupts = <0x0 0x40 0x4>;
			interrupt-names = "iommu-irq";
			clocks = <0x2a>;
			clock-names = "iommu";
			iova-base = <0x48400000>;
			#iommu-cells = <0x2>;
			status = "okay";
			linux,phandle = <0x24>;
			phandle = <0x24>;
		};

		mbus-controller@0x3102000 {
			compatible = "allwinner,sun8i-mbus";
			reg = <0x0 0x3102000 0x0 0x1000>;
			#mbus-cells = <0x1>;
		};

		ce@03040000 {
			compatible = "allwinner,sunxi-ce";
			device_name = "ce";
			reg = <0x0 0x3040000 0x0 0xa0 0x0 0x3040800 0x0 0xa0>;
			interrupts = <0x0 0x34 0x1 0x0 0x35 0x1>;
			clocks = <0x2b 0x6>;
		};

		spi@04025000 {
			#address-cells = <0x1>;
			#size-cells = <0x0>;
			compatible = "allwinner,sun8i-spi";
			device_type = "spi0";
			reg = <0x0 0x4025000 0x0 0x1000>;
			interrupts = <0x0 0xf 0x4>;
			clocks = <0x8 0x2c>;
			status = "disabled";
			clock-frequency = <0x5f5e100>;
			pinctrl-0 = <0x2d 0x2e>;
			pinctrl-1 = <0x2f>;
			spi-supply = <0x30>;
			pinctrl-names = "default", "sleep";
			spi_slave_mode = <0x0>;
			spi_dbi_enable = <0x0>;
			spi0_cs_number = <0x1>;

			spi_board0 {
				device_type = "spi_board0";
				compatible = "spi-nor";
				spi-max-frequency = <0x5f5e100>;
				m25p,fast-read = <0x1>;
				reg = <0x0>;
				spi-rx-bus-width = <0x4>;
				spi-tx-bus-width = <0x4>;
				status = "disabled";
			};

			spi-nand@0 {
				compatible = "spi-nand";
				spi-max-frequency = <0x5f5e100>;
				reg = <0x0>;
				spi-rx-bus-width = <0x4>;
				spi-tx-bus-width = <0x4>;
				status = "disabled";
			};
		};

		spi@04026000 {
			#address-cells = <0x1>;
			#size-cells = <0x0>;
			compatible = "allwinner,sun8i-spi";
			device_type = "spi-dbi";
			reg = <0x0 0x4025000 0x0 0x1000>;
			interrupts = <0x0 0xf 0x4>;
			clocks = <0x8 0x31>;
			status = "disabled";
			clock-frequency = <0x5f5e100>;
			pinctrl-0 = <0x32 0x33>;
			pinctrl-1 = <0x34>;
			pinctrl-names = "default", "sleep";
			spi_slave_mode = <0x0>;
			spi_dbi_enable = <0x1>;
			spi1_cs_number = <0x1>;

			spi_board1@0 {
				device_type = "spi_dbi";
				compatible = "sunxi,spidbi";
				spi-max-frequency = <0x5f5e100>;
				reg = <0x0>;
				spi-rx-bus-width = <0x4>;
				spi-tx-bus-width = <0x4>;
				status = "disabled";
			};
		};

		spi@04028000 {
			#address-cells = <0x1>;
			#size-cells = <0x0>;
			compatible = "allwinner,sun8i-spi";
			device_type = "spi3";
			reg = <0x0 0x4028000 0x0 0x1000>;
			interrupts = <0x0 0x15 0x4>;
			clocks = <0x8 0x35>;
			status = "disabled";
		};

		spif@04f00000 {
			#address-cells = <0x1>;
			#size-cells = <0x0>;
			compatible = "allwinner,sun8i-spif";
			device_type = "spif0";
			reg = <0x0 0x4f00000 0x0 0x1000>;
			interrupts = <0x0 0x13 0x4>;
			clocks = <0x8 0x36>;
			clock-names = "pclk", "mclk";
			status = "disabled";
			clock-frequency = <0x989680>;
			pinctrl-0 = <0x37 0x38>;
			pinctrl-1 = <0x39>;
			pinctrl-names = "default", "sleep";

			spi_board1@0 {
				device_type = "spi_board1";
				compatible = "rohm,dh2228fv";
				spi-max-frequency = <0x5f5e100>;
				reg = <0x0>;
				spi-rx-bus-width = <0x4>;
				spi-tx-bus-width = <0x4>;
				status = "disabled";
			};
		};

		msgbox@3003000 {
			compatible = "allwinner,sunxi-msgbox";
			#mbox-cells = <0x1>;
			reg = <0x0 0x3003000 0x0 0x1000 0x0 0x6020000 0x0 0x1000>;
			interrupts = <0x0 0x0 0x4 0x0 0x1 0x4>;
			clocks = <0x3a>;
			clock-names = "msgbox0";
			local_id = <0x0>;
			status = "okay";
			linux,phandle = <0xb0>;
			phandle = <0xb0>;
		};

		twi@0x02502000 {
			#address-cells = <0x1>;
			#size-cells = <0x0>;
			compatible = "allwinner,sun8i-twi";
			device_type = "twi0";
			reg = <0x0 0x2502000 0x0 0x400>;
			interrupts = <0x0 0x9 0x4>;
			clocks = <0x3b>;
			status = "okay";
			clock-frequency = <0x61a80>;
			pinctrl-0 = <0x3c>;
			pinctrl-1 = <0x3d>;
			pinctrl-names = "default", "sleep";
			twi_drv_used = <0x0>;
			twi-supply = <0x1a>;
			twi_pkt_interval = <0x0>;
		};

		twi@0x02502400 {
			#address-cells = <0x1>;
			#size-cells = <0x0>;
			compatible = "allwinner,sun8i-twi";
			device_type = "twi1";
			reg = <0x0 0x2502400 0x0 0x400>;
			interrupts = <0x0 0xa 0x4>;
			clocks = <0x3e>;
			status = "okay";
			clock-frequency = <0x61a80>;
			pinctrl-0 = <0x3f>;
			pinctrl-1 = <0x40>;
			pinctrl-names = "default", "sleep";
			twi_drv_used = <0x0>;
			twi-supply = <0x1a>;
			twi_pkt_interval = <0x0>;
		};

		twi@0x02502800 {
			#address-cells = <0x1>;
			#size-cells = <0x0>;
			compatible = "allwinner,sun50i-twi";
			device_type = "twi2";
			reg = <0x0 0x2502800 0x0 0x400>;
			interrupts = <0x0 0xb 0x4>;
			clocks = <0x41>;
			status = "okay";
			clock-frequency = <0x61a80>;
			pinctrl-0 = <0x42>;
			pinctrl-1 = <0x43>;
			pinctrl-names = "default", "sleep";
			twi_drv_used = <0x0>;
			twi-supply = <0x1a>;
			twi_pkt_interval = <0x0>;

			ctp@14 {
				compatible = "allwinner,gsl3680";
				device_type = "ctp";
				reg = <0x40>;
				status = "okay";
				ctp_name = "gslX680_3680";
				ctp_twi_id = <0x2>;
				ctp_twi_addr = <0x40>;
				ctp_screen_max_x = <0x500>;
				ctp_screen_max_y = <0x320>;
				ctp_revert_x_flag = <0x0>;
				ctp_revert_y_flag = <0x1>;
				ctp_exchange_x_y_flag = <0x1>;
				ctp_int_port = <0x26 0x7 0x7 0x6 0x1 0x3 0xffffffff>;
				ctp_wakeup = <0x26 0x7 0x8 0x1 0x1 0x3 0xffffffff>;
			};
		};

		twi@0x02502c00 {
			#address-cells = <0x1>;
			#size-cells = <0x0>;
			compatible = "allwinner,sun8i-twi";
			device_type = "twi3";
			reg = <0x0 0x2502c00 0x0 0x400>;
			interrupts = <0x0 0xc 0x4>;
			clocks = <0x44>;
			status = "okay";
			clock-frequency = <0x61a80>;
			pinctrl-0 = <0x45>;
			pinctrl-1 = <0x46>;
			pinctrl-names = "default", "sleep";
			twi_drv_used = <0x0>;
			twi-supply = <0x47>;
			twi_pkt_interval = <0x0>;

			da380 {
				status = "okay";
				compatible = "da380";
				reg = <0x27>;
			};
		};

		twi@0x02503000 {
			#address-cells = <0x1>;
			#size-cells = <0x0>;
			compatible = "allwinner,sun8i-twi";
			device_type = "twi4";
			reg = <0x0 0x2503000 0x0 0x400>;
			interrupts = <0x0 0xd 0x4>;
			clocks = <0x48>;
			status = "okay";
			clock-frequency = <0x61a80>;
			pinctrl-0 = <0x49>;
			pinctrl-1 = <0x4a>;
			pinctrl-names = "default", "sleep";
			twi_drv_used = <0x0>;
			twi-supply = <0x47>;
			twi_pkt_interval = <0x0>;
			no_suspend = <0x1>;

			pmu@0 {
				compatible = "x-powers,axp2101";
				reg = <0x34>;
				#address-cells = <0x1>;
				#size-cells = <0x0>;
				interrupts = <0x0 0x8>;
				interrupt-parent = <0x4b>;
				status = "okay";
				wakeup-source;

				charger@0 {
					compatible = "x-powers,axp2101-power-supply";
					param = <0x4c>;
					status = "okay";
					pmu_chg_ic_temp = <0x0>;
					pmu_battery_cap = <0x378>;
					pmu_runtime_chgcur = <0x1f4>;
					pmu_suspend_chgcur = <0x3e8>;
					pmu_shutdown_chgcur = <0x3e8>;
					pmu_init_chgvol = <0x1068>;
					pmu_usbpc_cur = <0x7d0>;
					pmu_battery_warning_level1 = <0xf>;
					pmu_battery_warning_level2 = <0x5>;
					pmu_chgled_type = <0x0>;
					wakeup_usb_in;
					wakeup_usb_out;
					wakeup_bat_out;
				};

				powerkey@0 {
					status = "okay";
					compatible = "x-powers,axp2101-pek";
					pmu_powkey_off_time = <0x1770>;
					pmu_powkey_off_func = <0x0>;
					pmu_powkey_off_en = <0x1>;
					pmu_powkey_long_time = <0x5dc>;
					pmu_powkey_on_time = <0x200>;
					wakeup_rising;
					wakeup_falling;
				};

				regulators@0 {

					dcdc1 {
						regulator-name = "axp2101-dcdc1";
						regulator-min-microvolt = <0x16e360>;
						regulator-max-microvolt = <0x33e140>;
						regulator-boot-on;
						regulator-always-on;
						linux,phandle = <0x1a>;
						phandle = <0x1a>;
					};

					dcdc2 {
						regulator-name = "axp2101-dcdc2";
						regulator-min-microvolt = <0x7a120>;
						regulator-max-microvolt = <0x177fa0>;
						linux,phandle = <0x4d>;
						phandle = <0x4d>;
					};

					dcdc3 {
						regulator-name = "axp2101-dcdc3";
						regulator-min-microvolt = <0x7a120>;
						regulator-max-microvolt = <0x33e140>;
						regulator-boot-on;
						regulator-always-on;
						linux,phandle = <0x30>;
						phandle = <0x30>;
					};

					dcdc4 {
						regulator-name = "axp2101-dcdc4";
						regulator-min-microvolt = <0x7a120>;
						regulator-max-microvolt = <0x1c1380>;
						regulator-boot-on;
						regulator-always-on;
						linux,phandle = <0x4e>;
						phandle = <0x4e>;
					};

					dcdc5 {
						regulator-name = "axp2101-dcdc5";
						regulator-min-microvolt = <0x155cc0>;
						regulator-max-microvolt = <0x387520>;
						linux,phandle = <0x4f>;
						phandle = <0x4f>;
					};

					rtcldo {
						regulator-name = "axp2101-rtcldo";
						regulator-min-microvolt = <0x1b7740>;
						regulator-max-microvolt = <0x1b7740>;
						regulator-boot-on;
						regulator-always-on;
					};

					rtcldo1 {
						regulator-name = "axp2101-rtcldo1";
						regulator-min-microvolt = <0x1b7740>;
						regulator-max-microvolt = <0x1b7740>;
					};

					aldo1 {
						regulator-name = "axp2101-aldo1";
						regulator-min-microvolt = <0x7a120>;
						regulator-max-microvolt = <0x3567e0>;
						regulator-boot-on;
						regulator-always-on;
						linux,phandle = <0x47>;
						phandle = <0x47>;
					};

					aldo2 {
						regulator-name = "axp2101-aldo2";
						regulator-min-microvolt = <0x7a120>;
						regulator-max-microvolt = <0x3567e0>;
						linux,phandle = <0x50>;
						phandle = <0x50>;
					};

					aldo3 {
						regulator-name = "axp2101-aldo3";
						regulator-min-microvolt = <0x7a120>;
						regulator-max-microvolt = <0x3567e0>;
						linux,phandle = <0x51>;
						phandle = <0x51>;
					};

					aldo4 {
						regulator-name = "axp2101-aldo4";
						regulator-min-microvolt = <0x7a120>;
						regulator-max-microvolt = <0x3567e0>;
						linux,phandle = <0x52>;
						phandle = <0x52>;
					};

					bldo1 {
						regulator-name = "axp2101-bldo1";
						regulator-min-microvolt = <0x7a120>;
						regulator-max-microvolt = <0x3567e0>;
						regulator-boot-on;
						regulator-always-on;
						linux,phandle = <0x53>;
						phandle = <0x53>;
					};

					bldo2 {
						regulator-name = "axp2101-bldo2";
						regulator-min-microvolt = <0x7a120>;
						regulator-max-microvolt = <0x3567e0>;
						linux,phandle = <0x54>;
						phandle = <0x54>;
					};

					dldo1 {
						regulator-name = "axp2101-dldo1";
						regulator-min-microvolt = <0x7a120>;
						regulator-max-microvolt = <0x3567e0>;
						regulator-boot-on;
						regulator-always-on;
						linux,phandle = <0x55>;
						phandle = <0x55>;
					};

					dldo2 {
						regulator-name = "axp2101-dldo2";
						regulator-min-microvolt = <0x7a120>;
						regulator-max-microvolt = <0x155cc0>;
						linux,phandle = <0x56>;
						phandle = <0x56>;
					};

					cpusldo {
						regulator-name = "axp2101-cpusldo";
						regulator-min-microvolt = <0x7a120>;
						regulator-max-microvolt = <0x155cc0>;
					};
				};

				virtual-dcdc1 {
					compatible = "xpower-vregulator,dcdc1";
					dcdc1-supply = <0x1a>;
				};

				virtual-dcdc2 {
					compatible = "xpower-vregulator,dcdc2";
					dcdc2-supply = <0x4d>;
				};

				virtual-dcdc3 {
					compatible = "xpower-vregulator,dcdc3";
					dcdc3-supply = <0x30>;
				};

				virtual-dcdc4 {
					compatible = "xpower-vregulator,dcdc4";
					dcdc4-supply = <0x4e>;
				};

				virtual-dcdc5 {
					compatible = "xpower-vregulator,dcdc5";
					dcdc5-supply = <0x4f>;
				};

				virtual-aldo1 {
					compatible = "xpower-vregulator,aldo1";
					aldo1-supply = <0x47>;
				};

				virtual-aldo2 {
					compatible = "xpower-vregulator,aldo2";
					aldo2-supply = <0x50>;
				};

				virtual-aldo3 {
					compatible = "xpower-vregulator,aldo3";
					aldo3-supply = <0x51>;
				};

				virtual-aldo4 {
					compatible = "xpower-vregulator,aldo4";
					aldo4-supply = <0x52>;
				};

				virtual-bldo1 {
					compatible = "xpower-vregulator,bldo1";
					bldo1-supply = <0x53>;
				};

				virtual-bldo2 {
					compatible = "xpower-vregulator,bldo2";
					bldo2-supply = <0x54>;
				};

				virtual-dldo1 {
					compatible = "xpower-vregulator,dldo1";
					dldo1-supply = <0x55>;
				};

				virtual-dldo2 {
					compatible = "xpower-vregulator,dldo2";
					dldo2-supply = <0x56>;
				};

				axp_gpio@0 {
					gpio-controller;
					#size-cells = <0x0>;
					#gpio-cells = <0x6>;
					status = "okay";
				};
			};
		};

		dma-controller@03002000 {
			compatible = "allwinner,sun8i-dma";
			reg = <0x0 0x3002000 0x0 0x1000>;
			interrupts = <0x0 0x32 0x4>;
			#dma-cells = <0x1>;
		};

		pwm@2000c00 {
			compatible = "allwinner,sunxi-pwm";
			reg = <0x0 0x2000c00 0x0 0x3f0>;
			clocks = <0x57>;
			pwm-number = <0xc>;
			pwm-base = <0x0>;
			pwms = <0x58 0x59 0x5a 0x5b 0x5c 0x5d 0x5e 0x5f 0x60 0x61 0x62 0x63>;
		};

		pwm0@2000c10 {
			compatible = "allwinner,sunxi-pwm0";
			reg = <0x0 0x2000c10 0x0 0x4>;
			reg_base = <0x2000c00>;
			linux,phandle = <0x58>;
			phandle = <0x58>;
		};

		pwm1@2000c11 {
			compatible = "allwinner,sunxi-pwm1";
			reg = <0x0 0x2000c11 0x0 0x4>;
			reg_base = <0x2000c00>;
			linux,phandle = <0x59>;
			phandle = <0x59>;
		};

		pwm2@2000c12 {
			compatible = "allwinner,sunxi-pwm2";
			reg = <0x0 0x2000c12 0x0 0x4>;
			reg_base = <0x2000c00>;
			linux,phandle = <0x5a>;
			phandle = <0x5a>;
		};

		pwm3@2000c13 {
			compatible = "allwinner,sunxi-pwm3";
			reg = <0x0 0x2000c13 0x0 0x4>;
			reg_base = <0x2000c00>;
			linux,phandle = <0x5b>;
			phandle = <0x5b>;
		};

		pwm4@2000c14 {
			compatible = "allwinner,sunxi-pwm4";
			reg = <0x0 0x2000c14 0x0 0x4>;
			reg_base = <0x2000c00>;
			pinctrl-names = "active", "sleep";
			pinctrl-0 = <0x64>;
			pinctrl-1 = <0x65>;
			status = "okay";
			linux,phandle = <0x5c>;
			phandle = <0x5c>;
		};

		pwm5@2000c15 {
			compatible = "allwinner,sunxi-pwm5";
			reg = <0x0 0x2000c15 0x0 0x4>;
			reg_base = <0x2000c00>;
			linux,phandle = <0x5d>;
			phandle = <0x5d>;
		};

		pwm6@2000c16 {
			compatible = "allwinner,sunxi-pwm6";
			reg = <0x0 0x2000c16 0x0 0x4>;
			reg_base = <0x2000c00>;
			linux,phandle = <0x5e>;
			phandle = <0x5e>;
		};

		pwm7@2000c17 {
			compatible = "allwinner,sunxi-pwm7";
			reg = <0x0 0x2000c17 0x0 0x4>;
			reg_base = <0x2000c00>;
			linux,phandle = <0x5f>;
			phandle = <0x5f>;
		};

		pwm8@2000c18 {
			compatible = "allwinner,sunxi-pwm8";
			reg = <0x0 0x2000c18 0x0 0x4>;
			reg_base = <0x2000c00>;
			linux,phandle = <0x60>;
			phandle = <0x60>;
		};

		pwm9@2000c19 {
			compatible = "allwinner,sunxi-pwm9";
			reg = <0x0 0x2000c19 0x0 0x4>;
			reg_base = <0x2000c00>;
			pinctrl-names = "active", "sleep";
			pinctrl-0 = <0x66>;
			pinctrl-1 = <0x67>;
			status = "okay";
			linux,phandle = <0x61>;
			phandle = <0x61>;
		};

		pwm10@2000c1a {
			compatible = "allwinner,sunxi-pwm10";
			reg = <0x0 0x2000c1a 0x0 0x4>;
			reg_base = <0x2000c00>;
			linux,phandle = <0x62>;
			phandle = <0x62>;
		};

		pwm11@2000c1b {
			compatible = "allwinner,sunxi-pwm11";
			reg = <0x0 0x2000c1b 0x0 0x4>;
			reg_base = <0x2000c00>;
			linux,phandle = <0x63>;
			phandle = <0x63>;
		};

		sid@3006000 {
			compatible = "allwinner,sun8iw21p1-sid", "allwinner,sunxi-sid";
			reg = <0x0 0x3006000 0x0 0x1000>;
			#address-cells = <0x1>;
			#size-cells = <0x1>;

			calib@14 {
				reg = <0x14 0x8>;
				linux,phandle = <0xba>;
				phandle = <0xba>;
			};
		};

		gpadc@2009000 {
			compatible = "allwinner,sunxi-gpadc";
			reg = <0x0 0x2009000 0x0 0x400>;
			interrupts = <0x0 0x39 0x0>;
			clocks = <0x12>;
			status = "okay";
			channel_num = <0x1>;
			channel_select = <0x1>;
			channel_data_select = <0x0>;
			channel_compare_select = <0x1>;
			channel_cld_select = <0x1>;
			channel_chd_select = <0x0>;
			channel0_compare_lowdata = <0x19f0a0>;
			channel0_compare_higdata = <0x124f80>;
			channel1_compare_lowdata = <0x704e0>;
			channel1_compare_higdata = <0x124f80>;
			key_cnt = <0x5>;
			key0_vol = <0xd2>;
			key0_val = <0x73>;
			key1_vol = <0x19a>;
			key1_val = <0x72>;
			key2_vol = <0x24e>;
			key2_val = <0x8b>;
			key3_vol = <0x2ee>;
			key3_val = <0x1c>;
			key4_vol = <0x370>;
			key4_val = <0x66>;
		};

		sdmmc@4022000 {
			compatible = "allwinner,sunxi-mmc-v4p6x";
			device_type = "sdc2";
			reg = <0x0 0x4022000 0x0 0x1000>;
			interrupts = <0x0 0x2a 0x4>;
			clocks = <0xc 0x5 0x68 0x69 0x6a>;
			clock-names = "osc24m", "pll_periph", "mmc", "ahb", "rst";
			pinctrl-names = "default", "sleep";
			pinctrl-0 = <0x6b 0x6c>;
			pinctrl-1 = <0x6d>;
			bus-width = <0x8>;
			req-page-count = <0x2>;
			cap-mmc-highspeed;
			cap-cmd23;
			mmc-cache-ctrl;
			non-removable;
			max-frequency = <0x5f5e100>;
			cap-erase;
			mmc-high-capacity-erase-size;
			no-sdio;
			no-sd;
			sdc_tm4_sm0_freq0 = <0x0>;
			sdc_tm4_sm0_freq1 = <0x0>;
			sdc_tm4_sm1_freq0 = <0x0>;
			sdc_tm4_sm1_freq1 = <0x0>;
			sdc_tm4_sm2_freq0 = <0x0>;
			sdc_tm4_sm2_freq1 = <0x0>;
			sdc_tm4_sm3_freq0 = <0x5000000>;
			sdc_tm4_sm3_freq1 = <0x5>;
			sdc_tm4_sm4_freq0 = <0x50000>;
			sdc_tm4_sm4_freq1 = <0x4>;
			sdc_tm4_sm4_freq0_cmd = <0x0>;
			sdc_tm4_sm4_freq1_cmd = <0x0>;
			ctl-spec-caps = <0x308>;
			status = "disabled";
			mmc-ddr-1_8v;
			mmc-hs200-1_8v;
			mmc-hs400-1_8v;
			sunxi-power-save-mode;
			sunxi-dis-signal-vol-sw;
			vmmc-supply = <0x1a>;
			vqmmc-supply = <0x53>;
		};

		sdmmc@4020000 {
			compatible = "allwinner,sunxi-mmc-v5p3x";
			device_type = "sdc0";
			reg = <0x0 0x4020000 0x0 0x1000>;
			interrupts = <0x0 0x28 0x4>;
			clocks = <0xc 0x8 0x6e 0x6f 0x70>;
			clock-names = "osc24m", "pll_periph", "mmc", "ahb", "rst";
			pinctrl-names = "default", "sleep", "uart_jtag";
			pinctrl-0 = <0x71>;
			pinctrl-1 = <0x72>;
			pinctrl-2 = <0x73>;
			max-frequency = <0x8f0d180>;
			bus-width = <0x4>;
			ctl-spec-caps = <0x408>;
			cap-sd-highspeed;
			cap-wait-while-busy;
			no-sdio;
			no-mmc;
			sunxi-dly-208M = <0x1 0x1 0x0 0x0 0x0 0x0>;
			cd-gpios = <0x26 0x5 0x6 0x6 0x1 0x3 0xffffffff>;
			card-pwr-gpios = <0x26 0x7 0xc 0x1 0x1 0x2 0xffffffff>;
			cd-used-24M;
			sd-uhs-sdr50;
			sd-uhs-ddr50;
			sd-uhs-sdr104;
			sunxi-signal-vol-sw-without-pmu;
			sunxi-power-save-mode;
			vmmc-supply = <0x1a>;
			vqmmc33sw-supply = <0x1a>;
			vdmmc33sw-supply = <0x1a>;
			vqmmc18sw-supply = <0x53>;
			vdmmc18sw-supply = <0x53>;
			status = "okay";
		};

		sdmmc@04021000 {
			compatible = "allwinner,sunxi-mmc-v5p3x";
			device_type = "sdc1";
			reg = <0x0 0x4021000 0x0 0x1000>;
			interrupts = <0x0 0x29 0x4>;
			clocks = <0xc 0x8 0x74 0x75 0x76>;
			clock-names = "osc24m", "pll_periph", "mmc", "ahb", "rst";
			pinctrl-names = "default", "sleep";
			pinctrl-0 = <0x77>;
			pinctrl-1 = <0x78>;
			max-frequency = <0x2faf080>;
			bus-width = <0x4>;
			ctl-spec-caps = <0x8>;
			cap-sd-highspeed;
			cap-mmc-highspeed;
			cap-wait-while-busy;
			sunxi-dly-52M-ddr4 = <0x1 0x0 0x0 0x0 0x2>;
			sunxi-dly-104M = <0x1 0x0 0x0 0x0 0x1>;
			sunxi-dly-208M = <0x1 0x1 0x0 0x0 0x0 0x0>;
			status = "okay";
			no-mmc;
			no-sd;
			sunxi-dis-signal-vol-sw;
			cap-sdio-irq;
			keep-power-in-suspend;
			ignore-pm-notify;
		};

		g2d@05410000 {
			compatible = "allwinner,sunxi-g2d";
			reg = <0x0 0x5410000 0x0 0xbffff>;
			interrupts = <0x0 0x59 0x4>;
			clocks = <0x10>;
			iommus = <0x24 0x3 0x1>;
			status = "okay";
		};

		disp@05000000 {
			compatible = "allwinner,sunxi-disp";
			reg = <0x0 0x5000000 0x0 0x300000 0x0 0x5460000 0x0 0xfff 0x0 0x5461000 0x0 0x7fc 0x0 0x5450000 0x0 0x10fc>;
			interrupts = <0x0 0x5a 0x4 0x0 0x5c 0x4>;
			clocks = <0xf 0x79 0x7a 0x13>;
			iommus = <0x24 0x2 0x0>;
			boot_disp = <0x0>;
			fb_base = <0x0>;
			status = "okay";
			disp_init_enable = <0x1>;
			disp_mode = <0x0>;
			screen0_output_type = <0x1>;
			screen0_output_mode = <0x4>;
			screen1_output_type = <0x3>;
			screen1_output_mode = <0xa>;
			screen1_output_format = <0x0>;
			screen1_output_bits = <0x0>;
			screen1_output_eotf = <0x4>;
			screen1_output_cs = <0x101>;
			screen1_output_range = <0x2>;
			screen1_output_scan = <0x0>;
			screen1_output_aspect_ratio = <0x8>;
			dev0_output_type = <0x1>;
			dev0_output_mode = <0x4>;
			dev0_screen_id = <0x0>;
			dev0_do_hpd = <0x0>;
			dev1_output_type = <0x4>;
			dev1_output_mode = <0xa>;
			dev1_screen_id = <0x1>;
			dev1_do_hpd = <0x1>;
			def_output_dev = <0x0>;
			fb0_format = <0x0>;
			fb0_width = <0x0>;
			fb0_height = <0x0>;
			fb1_format = <0x0>;
			fb1_width = <0x0>;
			fb1_height = <0x0>;
			chn_cfg_mode = <0x1>;
			disp_para_zone = <0x1>;
		};

		lcd0@05461000 {
			compatible = "allwinner,sunxi-lcd0";
			pinctrl-names = "active", "sleep";
			status = "okay";
			base_config_start = <0x1>;
			lcd_used = <0x1>;
			lcd_driver_name = "icn6202";
			lcd_bl_0_percent = <0x0>;
			lcd_bl_40_percent = <0x17>;
			lcd_bl_100_percent = <0x64>;
			lcd_backlight = <0x96>;
			lcd_if = <0x4>;
			lcd_x = <0x500>;
			lcd_y = <0x320>;
			lcd_width = <0x3e>;
			lcd_height = <0x6e>;
			lcd_dclk_freq = <0x47>;
			lcd_pwm_used = <0x1>;
			lcd_pwm_ch = <0x9>;
			lcd_pwm_freq = <0xc350>;
			lcd_pwm_pol = <0x0>;
			lcd_pwm_max_limit = <0xff>;
			lcd_hbp = <0x14>;
			lcd_ht = <0x58a>;
			lcd_hspw = <0xa>;
			lcd_vbp = <0xa>;
			lcd_vt = <0x33e>;
			lcd_vspw = <0x5>;
			lcd_dsi_if = <0x0>;
			lcd_dsi_lane = <0x4>;
			lcd_dsi_format = <0x0>;
			lcd_dsi_te = <0x0>;
			lcd_dsi_eotp = <0x0>;
			lcd_frm = <0x0>;
			lcd_io_phase = <0x0>;
			lcd_hv_clk_phase = <0x0>;
			lcd_hv_sync_polarity = <0x0>;
			lcd_gamma_en = <0x0>;
			lcd_bright_curve_en = <0x0>;
			lcd_cmap_en = <0x0>;
			lcdgamma4iep = <0x16>;
			lcd_gpio_0 = <0x26 0x3 0x13 0x1 0x0 0x3 0x1>;
			lcd_gpio_1 = <0x26 0x3 0x14 0x1 0x0 0x3 0x1>;
			pinctrl-0 = <0x7b>;
			pinctrl-1 = <0x7c>;
			base_config_end = <0x1>;
		};

		usbc0@0 {
			device_type = "usbc0";
			compatible = "allwinner,sunxi-otg-manager";
			usb_port_type = <0x2>;
			usb_detect_type = <0x1>;
			usb_id_gpio = <0x26 0x7 0xe 0x0 0x1 0xffffffff 0xffffffff>;
			usb_det_vbus_gpio = "axp_ctrl";
			usb_drv_vbus_gpio;
			usb_host_init_state = <0x0>;
			usb_regulator_io = "nocare";
			usb_wakeup_suspend = <0x0>;
			usb_luns = <0x3>;
			usb_serial_unique = <0x0>;
			usb_serial_number = "20080411";
			rndis_wceis = <0x1>;
			status = "okay";
			usb_detect_mode = <0x0>;
			det_vbus_supply = <0x7d>;
		};

		udc-controller@0x4100000 {
			compatible = "allwinner,sunxi-udc";
			reg = <0x0 0x4100000 0x0 0x1000 0x0 0x0 0x0 0x100>;
			interrupts = <0x0 0x1d 0x4>;
			clocks = <0x7e 0x7f>;
			status = "okay";
			det_vbus_supply = <0x7d>;
		};

		ehci0-controller@0x4101000 {
			compatible = "allwinner,sunxi-ehci0";
			reg = <0x0 0x4101000 0x0 0xfff 0x0 0x0 0x0 0x100 0x0 0x4100000 0x0 0x1000>;
			interrupts = <0x0 0x1e 0x4>;
			clocks = <0x7e 0x80>;
			hci_ctrl_no = <0x0>;
			status = "okay";
			drvvbus-supply = <0x81>;
		};

		ohci0-controller@0x4101400 {
			compatible = "allwinner,sunxi-ohci0";
			reg = <0x0 0x4101000 0x0 0xfff 0x0 0x0 0x0 0x100 0x0 0x4100000 0x0 0x1000>;
			interrupts = <0x0 0x1f 0x4>;
			clocks = <0x7e 0x82 0x83 0xd 0xc 0x15>;
			hci_ctrl_no = <0x0>;
			status = "okay";
			drvvbus-supply = <0x81>;
		};

		rtc@7090000 {
			compatible = "allwinner,sunxi-rtc";
			device_type = "rtc";
			auto_switch;
			wakeup-source;
			reg = <0x0 0x7090000 0x0 0x1a0>;
			interrupts = <0x0 0x8a 0x4>;
			gpr_offset = <0x100>;
			gpr_len = <0x8>;
			gpr_cur_pos = <0x6>;
		};

		codec@0x02030000 {
			#sound-dai-cells = <0x0>;
			compatible = "allwinner,sunxi-snd-codec";
			reg = <0x0 0x2030000 0x0 0x34c>;
			clocks = <0x84 0x85 0x86>;
			status = "okay";
			avcc-vol = <0x1b7740>;
			lineout-vol = <0x1f>;
			mic1gain = <0x1f>;
			mic2gain = <0x1f>;
			adcdelaytime = <0x0>;
			pa-pin-max = <0x1>;
			pa-pin-0 = <0x26 0x7 0x4 0x1 0x1 0x1 0x1>;
			pa-pin-level-0 = <0x1>;
			pa-pin-msleep-0 = <0x0>;
			tx-hub-en;
			rx-sync-en;
			linux,phandle = <0x88>;
			phandle = <0x88>;
		};

		codec_plat {
			#sound-dai-cells = <0x0>;
			compatible = "allwinner,sunxi-snd-plat-aaudio";
			playback-cma = <0x80>;
			capture-cma = <0x80>;
			tx-fifo-size = <0x80>;
			rx-fifo-size = <0x80>;
			dac-txdata = <0x2030020>;
			adc-txdata = <0x2030040>;
			status = "okay";
			linux,phandle = <0x87>;
			phandle = <0x87>;
		};

		codec_mach {
			compatible = "allwinner,sunxi-snd-mach";
			soundcard-mach,name = "audiocodec";
			soundcard-mach,pin-switches = "MIC1", "MIC2", "LINEIN", "LINEOUT", "SPK";
			soundcard-mach,routing = "MIC1_PIN", "MIC1", "MIC2_PIN", "MIC2", "LINEINL_PIN", "LINEIN", "LINEINR_PIN", "LINEIN", "LINEOUT", "LINEOUTL_PIN", "SPK", "LINEOUTL_PIN";
			status = "okay";

			soundcard-mach,cpu {
				sound-dai = <0x87>;
			};

			soundcard-mach,codec {
				soundcard-mach,pll-fs = <0x1>;
				sound-dai = <0x88>;
			};
		};

		dmic_plat@0x02031000 {
			#sound-dai-cells = <0x0>;
			compatible = "allwinner,sunxi-snd-plat-dmic";
			reg = <0x0 0x2031000 0x0 0x50>;
			clocks = <0x84 0x89>;
			capture-cma = <0x80>;
			rx_fifo-size = <0x80>;
			status = "disabled";
			rx-chmap = <0x76543210>;
			data-vol = <0xb0>;
			rxdelaytime = <0x0>;
			pinctrl-used;
			pinctrl-names = "default", "sleep";
			pinctrl-0 = <0x8a>;
			pinctrl-1 = <0x8b>;
			rx-sync-en;
			linux,phandle = <0x8c>;
			phandle = <0x8c>;
		};

		dmic_mach {
			compatible = "allwinner,sunxi-snd-mach";
			soundcard-mach,name = "snddmic";
			soundcard-mach,capture-only;
			status = "disabled";

			soundcard-mach,cpu {
				sound-dai = <0x8c>;
				soundcard-mach,pll-fs = <0x1>;
			};

			soundcard-mach,codec {
			};
		};

		daudio0_plat@0x02032000 {
			#sound-dai-cells = <0x0>;
			compatible = "allwinner,sunxi-snd-plat-daudio";
			reg = <0x0 0x2032000 0x0 0x7c>;
			clocks = <0x84 0x8d>;
			playback-cma = <0x80>;
			capture-cma = <0x80>;
			tx-fifo-size = <0x80>;
			rx-fifo-size = <0x80>;
			status = "okay";
			tdm-num = <0x0>;
			tx-pin = <0x0>;
			rx-pin = <0x0>;
			tx-hub-en;
			rx-sync-en;
			linux,phandle = <0x8f>;
			phandle = <0x8f>;
		};

		daudio0_mach {
			compatible = "allwinner,sunxi-snd-mach";
			soundcard-mach,format = "i2s";
			soundcard-mach,name = "snddaudio0";
			status = "okay";
			soundcard-mach,frame-master = <0x8e>;
			soundcard-mach,bitclock-master = <0x8e>;
			soundcard-mach,slot-num = <0x2>;
			soundcard-mach,slot-width = <0x20>;

			soundcard-mach,cpu {
				sound-dai = <0x8f>;
				soundcard-mach,pll-fs = <0x1>;
				soundcard-mach,mclk-fs = <0x0>;
				linux,phandle = <0x8e>;
				phandle = <0x8e>;
			};

			soundcard-mach,codec {
			};
		};

		daudio1_plat@0x02033000 {
			#sound-dai-cells = <0x0>;
			compatible = "allwinner,sunxi-snd-plat-daudio";
			reg = <0x0 0x2033000 0x0 0x7c>;
			clocks = <0x84 0x90>;
			playback-cma = <0x80>;
			capture-cma = <0x80>;
			tx-fifo-size = <0x80>;
			rx-fifo-size = <0x80>;
			status = "disabled";
			tdm-num = <0x1>;
			tx-pin = <0x0>;
			rx-pin = <0x0>;
			tx-hub-en;
			rx-sync-en;
			linux,phandle = <0x92>;
			phandle = <0x92>;
		};

		daudio1_mach {
			compatible = "allwinner,sunxi-snd-mach";
			soundcard-mach,format = "i2s";
			soundcard-mach,name = "snddaudio1";
			status = "disabled";
			soundcard-mach,frame-master = <0x91>;
			soundcard-mach,bitclock-master = <0x91>;
			soundcard-mach,slot-num = <0x2>;
			soundcard-mach,slot-width = <0x20>;

			soundcard-mach,cpu {
				sound-dai = <0x92>;
				soundcard-mach,pll-fs = <0x1>;
				soundcard-mach,mclk-fs = <0x0>;
				linux,phandle = <0x91>;
				phandle = <0x91>;
			};

			soundcard-mach,codec {
			};
		};

		wiegand@0x02020000 {
			compatible = "allwinner,sunxi-wiegand";
			reg = <0x0 0x2020000 0x0 0x200>;
			interrupts = <0x0 0x14 0x4>;
			clocks = <0x93 0x14>;
			clock-names = "pclk", "wclk";
			status = "okay";
			protocol-type = <0x0>;
			signal-duration = <0x6e>;
			signal-period = <0x49a>;
			high-parity-polar = <0x1>;
			low-parity-polar = <0x0>;
			data-polar = <0x1>;
			clock-div = <0x18>;
			pinctrl-names = "default", "sleep";
			pinctrl-0 = <0x94>;
			pinctrl-1 = <0x95>;
		};

		eth@4500000 {
			compatible = "allwinner,sunxi-gmac";
			reg = <0x0 0x4500000 0x0 0x10000 0x0 0x3000030 0x0 0x4>;
			interrupts = <0x0 0x2e 0x4>;
			interrupt-names = "gmacirq";
			clocks = <0x96 0x97>;
			clock-names = "gmac", "ephy";
			device_type = "gmac0";
			gmac-power0;
			gmac-power1;
			gmac-power2;
			status = "disabled";
			phy-mode = "rmii";
			use_ephy25m = <0x1>;
			pinctrl-0 = <0x98>;
			pinctrl-1 = <0x99>;
			pinctrl-names = "default", "sleep";
			tx-delay = <0x7>;
			rx-delay = <0x1f>;
		};

		vind@0 {
			compatible = "allwinner,sunxi-vin-media", "simple-bus";
			#address-cells = <0x2>;
			#size-cells = <0x2>;
			ranges;
			device_id = <0x0>;
			vind0_clk = <0x11e1a300>;
			reg = <0x0 0x5800800 0x0 0x200 0x0 0x5800000 0x0 0x800 0x0 0x5810000 0x0 0x100>;
			interrupts = <0x0 0x6a 0x4>;
			clocks = <0x9a 0x9b 0x9c 0xc 0x9b 0x9d 0xc 0x9b 0x9e 0xc 0x9b 0x9f 0x8 0x6>;
			pinctrl-names = "mclk0-default", "mclk0-sleep", "mclk1-default", "mclk1-sleep", "mclk2-default", "mclk2-sleep";
			pinctrl-0 = <0xa0>;
			pinctrl-1 = <0xa1>;
			pinctrl-2 = <0xa2>;
			pinctrl-3 = <0xa3>;
			pinctrl-4 = <0xa4>;
			pinctrl-5 = <0xa5>;
			status = "okay";

			csi@0 {
				device_type = "csi0";
				compatible = "allwinner,sunxi-csi";
				reg = <0x0 0x5820000 0x0 0x1000>;
				interrupts = <0x0 0x64 0x4>;
				device_id = <0x0>;
				status = "okay";
			};

			csi@1 {
				device_type = "csi1";
				compatible = "allwinner,sunxi-csi";
				reg = <0x0 0x5821000 0x0 0x1000>;
				interrupts = <0x0 0x65 0x4>;
				device_id = <0x1>;
				status = "okay";
			};

			csi@2 {
				device_type = "csi2";
				compatible = "allwinner,sunxi-csi";
				reg = <0x0 0x5822000 0x0 0x1000>;
				interrupts = <0x0 0x66 0x4>;
				pinctrl-names = "default", "sleep";
				pinctrl-0 = <0xa6>;
				pinctrl-1 = <0xa7>;
				device_id = <0x2>;
				status = "okay";
			};

			mipi@0 {
				compatible = "allwinner,sunxi-mipi";
				reg = <0x0 0x5810100 0x0 0x100 0x0 0x5811000 0x0 0x400>;
				interrupts = <0x0 0x68 0x4>;
				pinctrl-names = "mipi0-default", "mipi0-sleep", "mipi1-4lane-default", "mipi1-4lane-sleep";
				pinctrl-0 = <0xa8>;
				pinctrl-1 = <0xa9>;
				pinctrl-2 = <0xaa>;
				pinctrl-3 = <0xab>;
				device_id = <0x0>;
				status = "okay";
			};

			mipi@1 {
				compatible = "allwinner,sunxi-mipi";
				reg = <0x0 0x5810200 0x0 0x100 0x0 0x5811400 0x0 0x400>;
				pinctrl-names = "mipi1-default", "mipi1-sleep";
				pinctrl-0 = <0xac>;
				pinctrl-1 = <0xad>;
				device_id = <0x1>;
				status = "okay";
			};

			tdm@0 {
				compatible = "allwinner,sunxi-tdm";
				reg = <0x0 0x5908000 0x0 0x340>;
				interrupts = <0x0 0x69 0x4>;
				device_id = <0x0>;
				work_mode = <0x0>;
				iommus = <0x24 0x4 0x1>;
				status = "okay";
			};

			isp@0 {
				compatible = "allwinner,sunxi-isp";
				reg = <0x0 0x5900000 0x0 0x1300 0x0 0x3000000 0x0 0x10>;
				interrupts = <0x0 0x6c 0x4>;
				work_mode = <0x0>;
				device_id = <0x0>;
				iommus = <0x24 0x4 0x1>;
				status = "okay";
			};

			isp@1 {
				compatible = "allwinner,sunxi-isp";
				reg = <0x0 0x58ffffc 0x0 0x1304>;
				interrupts = <0x0 0x6d 0x4>;
				work_mode = <0xff>;
				device_id = <0x1>;
				iommus = <0x24 0x4 0x1>;
				status = "okay";
			};

			isp@2 {
				compatible = "allwinner,sunxi-isp";
				reg = <0x0 0x58ffff8 0x0 0x1308>;
				interrupts = <0x0 0x6e 0x4>;
				work_mode = <0xff>;
				device_id = <0x2>;
				iommus = <0x24 0x4 0x1>;
				status = "okay";
			};

			isp@3 {
				compatible = "allwinner,sunxi-isp";
				reg = <0x0 0x58ffff4 0x0 0x130c>;
				interrupts = <0x0 0x6f 0x4>;
				work_mode = <0xff>;
				device_id = <0x3>;
				iommus = <0x24 0x4 0x1>;
				status = "okay";
			};

			isp@4 {
				compatible = "allwinner,sunxi-isp";
				device_id = <0x4>;
				iommus = <0x24 0x4 0x1>;
				status = "okay";
			};

			scaler@0 {
				compatible = "allwinner,sunxi-scaler";
				reg = <0x0 0x5910000 0x0 0x400>;
				interrupts = <0x0 0x70 0x4>;
				work_mode = <0x0>;
				device_id = <0x0>;
				iommus = <0x24 0x1 0x1>;
				status = "okay";
			};

			scaler@1 {
				compatible = "allwinner,sunxi-scaler";
				reg = <0x0 0x590fffc 0x0 0x404>;
				work_mode = <0xff>;
				device_id = <0x1>;
				iommus = <0x24 0x1 0x1>;
				status = "okay";
			};

			scaler@2 {
				compatible = "allwinner,sunxi-scaler";
				reg = <0x0 0x590fff8 0x0 0x408>;
				work_mode = <0xff>;
				device_id = <0x2>;
				iommus = <0x24 0x1 0x1>;
				status = "okay";
			};

			scaler@3 {
				compatible = "allwinner,sunxi-scaler";
				reg = <0x0 0x590fff4 0x0 0x40c>;
				work_mode = <0xff>;
				device_id = <0x3>;
				iommus = <0x24 0x1 0x1>;
				status = "okay";
			};

			scaler@4 {
				compatible = "allwinner,sunxi-scaler";
				reg = <0x0 0x5910400 0x0 0x400>;
				interrupts = <0x0 0x71 0x4>;
				work_mode = <0x0>;
				device_id = <0x4>;
				iommus = <0x24 0x1 0x1>;
				status = "okay";
			};

			scaler@5 {
				compatible = "allwinner,sunxi-scaler";
				reg = <0x0 0x59103fc 0x0 0x404>;
				work_mode = <0xff>;
				device_id = <0x5>;
				iommus = <0x24 0x1 0x1>;
				status = "okay";
			};

			scaler@6 {
				compatible = "allwinner,sunxi-scaler";
				reg = <0x0 0x59103f8 0x0 0x408>;
				work_mode = <0xff>;
				device_id = <0x6>;
				iommus = <0x24 0x1 0x1>;
				status = "okay";
			};

			scaler@7 {
				compatible = "allwinner,sunxi-scaler";
				reg = <0x0 0x59103f4 0x0 0x40c>;
				work_mode = <0xff>;
				device_id = <0x7>;
				iommus = <0x24 0x1 0x1>;
				status = "okay";
			};

			scaler@8 {
				compatible = "allwinner,sunxi-scaler";
				reg = <0x0 0x5910800 0x0 0x400>;
				interrupts = <0x0 0x72 0x4>;
				work_mode = <0x0>;
				device_id = <0x8>;
				iommus = <0x24 0x1 0x1>;
				status = "okay";
			};

			scaler@9 {
				compatible = "allwinner,sunxi-scaler";
				reg = <0x0 0x59107fc 0x0 0x404>;
				work_mode = <0xff>;
				device_id = <0x9>;
				iommus = <0x24 0x1 0x1>;
				status = "okay";
			};

			scaler@10 {
				compatible = "allwinner,sunxi-scaler";
				reg = <0x0 0x59107f8 0x0 0x408>;
				work_mode = <0xff>;
				device_id = <0xa>;
				iommus = <0x24 0x1 0x1>;
				status = "okay";
			};

			scaler@11 {
				compatible = "allwinner,sunxi-scaler";
				reg = <0x0 0x59107f4 0x0 0x40c>;
				work_mode = <0xff>;
				device_id = <0xb>;
				iommus = <0x24 0x1 0x1>;
				status = "okay";
			};

			scaler@12 {
				compatible = "allwinner,sunxi-scaler";
				reg = <0x0 0x5910c00 0x0 0x400>;
				interrupts = <0x0 0x73 0x4>;
				work_mode = <0x0>;
				device_id = <0xc>;
				iommus = <0x24 0x1 0x1>;
				status = "okay";
			};

			scaler@13 {
				compatible = "allwinner,sunxi-scaler";
				reg = <0x0 0x5910bfc 0x0 0x404>;
				work_mode = <0xff>;
				device_id = <0xd>;
				iommus = <0x24 0x1 0x1>;
				status = "okay";
			};

			scaler@14 {
				compatible = "allwinner,sunxi-scaler";
				reg = <0x0 0x5910bf8 0x0 0x408>;
				work_mode = <0xff>;
				device_id = <0xe>;
				iommus = <0x24 0x1 0x1>;
				status = "okay";
			};

			scaler@15 {
				compatible = "allwinner,sunxi-scaler";
				reg = <0x0 0x5910bf4 0x0 0x40c>;
				work_mode = <0xff>;
				device_id = <0xf>;
				iommus = <0x24 0x1 0x1>;
				status = "okay";
			};

			actuator@0 {
				device_type = "actuator0";
				compatible = "allwinner,sunxi-actuator";
				actuator0_name = "ad5820_act";
				actuator0_slave = <0x18>;
				actuator0_af_pwdn;
				actuator0_afvdd = "afvcc-csi";
				actuator0_afvdd_vol = <0x2ab980>;
				status = "disabled";
				linux,phandle = <0xaf>;
				phandle = <0xaf>;
			};

			flash@0 {
				device_type = "flash0";
				compatible = "allwinner,sunxi-flash";
				flash0_type = <0x2>;
				flash0_en;
				flash0_mode;
				flash0_flvdd = [00];
				flash0_flvdd_vol;
				device_id = <0x0>;
				status = "disabled";
				linux,phandle = <0xae>;
				phandle = <0xae>;
			};

			sensor@0 {
				device_type = "sensor0";
				compatible = "allwinner,sunxi-sensor";
				sensor0_mname = "gc2053_mipi";
				sensor0_twi_cci_id = <0x1>;
				sensor0_twi_addr = <0x6e>;
				sensor0_mclk_id = <0x0>;
				sensor0_pos = "rear";
				sensor0_isp_used = <0x1>;
				sensor0_fmt = <0x1>;
				sensor0_stby_mode = <0x0>;
				sensor0_vflip = <0x0>;
				sensor0_hflip = <0x0>;
				sensor0_iovdd-supply = <0x50>;
				sensor0_iovdd_vol = <0x1b7740>;
				sensor0_avdd-supply = <0x54>;
				sensor0_avdd_vol = <0x2ab980>;
				sensor0_dvdd-supply = <0x56>;
				sensor0_dvdd_vol = <0x124f80>;
				sensor0_power_en;
				sensor0_reset = <0x26 0x0 0x12 0x1 0x0 0x1 0x0>;
				sensor0_pwdn = <0x26 0x0 0x13 0x1 0x0 0x1 0x0>;
				sensor0_sm_hs;
				sensor0_sm_vs;
				flash_handle = <0xae>;
				act_handle = <0xaf>;
				device_id = <0x0>;
				status = "okay";
			};

			sensor@1 {
				device_type = "sensor1";
				compatible = "allwinner,sunxi-sensor";
				sensor1_mname = "tp9953";
				sensor1_twi_cci_id = <0x0>;
				sensor1_twi_addr = <0x88>;
				sensor1_mclk_id = <0x2>;
				sensor1_pos = "front";
				sensor1_isp_used = <0x0>;
				sensor1_fmt = <0x0>;
				sensor1_stby_mode = <0x0>;
				sensor1_vflip = <0x0>;
				sensor1_hflip = <0x0>;
				sensor1_iovdd-supply = <0x50>;
				sensor1_iovdd_vol = <0x1b7740>;
				sensor1_avdd-supply;
				sensor1_avdd_vol = <0x325aa0>;
				sensor1_dvdd-supply;
				sensor1_dvdd_vol = <0x124f80>;
				sensor1_power_en = <0x26 0x8 0x0 0x1 0x0 0x1 0x0>;
				sensor1_reset = <0x26 0x7 0xd 0x1 0x0 0x1 0x0>;
				sensor1_pwdn;
				sensor1_sm_hs;
				sensor1_sm_vs;
				flash_handle;
				act_handle;
				device_id = <0x1>;
				status = "okay";
			};

			vinc@0 {
				device_type = "vinc0";
				compatible = "allwinner,sunxi-vin-core";
				reg = <0x0 0x5830000 0x0 0x1000>;
				interrupts = <0x0 0x5f 0x4>;
				vinc0_csi_sel = <0x0>;
				vinc0_mipi_sel = <0x0>;
				vinc0_isp_sel = <0x0>;
				vinc0_isp_tx_ch = <0x0>;
				vinc0_tdm_rx_sel = <0x0>;
				vinc0_rear_sensor_sel = <0x0>;
				vinc0_front_sensor_sel = <0x0>;
				vinc0_sensor_list = <0x0>;
				device_id = <0x0>;
				work_mode = <0x1>;
				iommus = <0x24 0x1 0x1>;
				status = "okay";
			};

			vinc@1 {
				device_type = "vinc1";
				compatible = "allwinner,sunxi-vin-core";
				reg = <0x0 0x582fffc 0x0 0x1004>;
				vinc1_csi_sel = <0x1>;
				vinc1_mipi_sel = <0x1>;
				vinc1_isp_sel = <0x1>;
				vinc1_isp_tx_ch = <0x0>;
				vinc1_tdm_rx_sel = <0x1>;
				vinc1_rear_sensor_sel = <0x1>;
				vinc1_front_sensor_sel = <0x1>;
				vinc1_sensor_list = <0x0>;
				device_id = <0x1>;
				work_mode = <0xff>;
				iommus = <0x24 0x1 0x1>;
				status = "disabled";
			};

			vinc@2 {
				device_type = "vinc2";
				compatible = "allwinner,sunxi-vin-core";
				reg = <0x0 0x582fff8 0x0 0x1008>;
				vinc2_csi_sel = <0x2>;
				vinc2_mipi_sel = <0xff>;
				vinc2_isp_sel = <0x2>;
				vinc2_isp_tx_ch = <0x2>;
				vinc2_tdm_rx_sel = <0x2>;
				vinc2_rear_sensor_sel = <0x0>;
				vinc2_front_sensor_sel = <0x0>;
				vinc2_sensor_list = <0x0>;
				device_id = <0x2>;
				work_mode = <0xff>;
				iommus = <0x24 0x1 0x1>;
				status = "disabled";
			};

			vinc@3 {
				device_type = "vinc3";
				compatible = "allwinner,sunxi-vin-core";
				reg = <0x0 0x582fff4 0x0 0x100c>;
				vinc3_csi_sel = <0x0>;
				vinc3_mipi_sel = <0xff>;
				vinc3_isp_sel = <0x0>;
				vinc3_isp_tx_ch = <0x0>;
				vinc3_tdm_rx_sel = <0x0>;
				vinc3_rear_sensor_sel = <0x1>;
				vinc3_front_sensor_sel = <0x1>;
				vinc3_sensor_list = <0x0>;
				device_id = <0x3>;
				work_mode = <0xff>;
				iommus = <0x24 0x1 0x1>;
				status = "disabled";
			};

			vinc@4 {
				device_type = "vinc4";
				compatible = "allwinner,sunxi-vin-core";
				reg = <0x0 0x5831000 0x0 0x1000>;
				interrupts = <0x0 0x60 0x4>;
				vinc4_csi_sel = <0x2>;
				vinc4_mipi_sel = <0xff>;
				vinc4_isp_sel = <0x4>;
				vinc4_isp_tx_ch = <0x0>;
				vinc4_tdm_rx_sel = <0xff>;
				vinc4_rear_sensor_sel = <0x1>;
				vinc4_front_sensor_sel = <0x1>;
				vinc4_sensor_list = <0x0>;
				device_id = <0x4>;
				work_mode = <0x0>;
				iommus = <0x24 0x1 0x1>;
				status = "okay";
			};

			vinc@5 {
				device_type = "vinc5";
				compatible = "allwinner,sunxi-vin-core";
				reg = <0x0 0x5830ffc 0x0 0x1004>;
				vinc5_csi_sel = <0x1>;
				vinc5_mipi_sel = <0x1>;
				vinc5_isp_sel = <0x1>;
				vinc5_isp_tx_ch = <0x0>;
				vinc5_tdm_rx_sel = <0x1>;
				vinc5_rear_sensor_sel = <0x1>;
				vinc5_front_sensor_sel = <0x1>;
				vinc5_sensor_list = <0x0>;
				device_id = <0x5>;
				work_mode = <0xff>;
				iommus = <0x24 0x1 0x1>;
				status = "disabled";
			};

			vinc@6 {
				device_type = "vinc6";
				compatible = "allwinner,sunxi-vin-core";
				reg = <0x0 0x5830ff8 0x0 0x1008>;
				vinc6_csi_sel = <0x2>;
				vinc6_mipi_sel = <0xff>;
				vinc6_isp_sel = <0x0>;
				vinc6_isp_tx_ch = <0x0>;
				vinc6_tdm_rx_sel = <0x0>;
				vinc6_rear_sensor_sel = <0x0>;
				vinc6_front_sensor_sel = <0x0>;
				vinc6_sensor_list = <0x0>;
				device_id = <0x6>;
				work_mode = <0xff>;
				iommus = <0x24 0x1 0x1>;
				status = "disabled";
			};

			vinc@7 {
				device_type = "vinc7";
				compatible = "allwinner,sunxi-vin-core";
				reg = <0x0 0x5830ff4 0x0 0x100c>;
				vinc7_csi_sel = <0x2>;
				vinc7_mipi_sel = <0xff>;
				vinc7_isp_sel = <0x0>;
				vinc7_isp_tx_ch = <0x0>;
				vinc7_tdm_rx_sel = <0x0>;
				vinc7_rear_sensor_sel = <0x0>;
				vinc7_front_sensor_sel = <0x0>;
				vinc7_sensor_list = <0x0>;
				device_id = <0x7>;
				work_mode = <0xff>;
				iommus = <0x24 0x1 0x1>;
				status = "disabled";
			};

			vinc@8 {
				device_type = "vinc8";
				compatible = "allwinner,sunxi-vin-core";
				reg = <0x0 0x5832000 0x0 0x1000>;
				interrupts = <0x0 0x61 0x4>;
				vinc8_csi_sel = <0x2>;
				vinc8_mipi_sel = <0xff>;
				vinc8_isp_sel = <0x4>;
				vinc8_isp_tx_ch = <0x1>;
				vinc8_tdm_rx_sel = <0xff>;
				vinc8_rear_sensor_sel = <0x1>;
				vinc8_front_sensor_sel = <0x1>;
				vinc8_sensor_list = <0x0>;
				device_id = <0x8>;
				work_mode = <0x0>;
				iommus = <0x24 0x1 0x1>;
				status = "okay";
			};

			vinc@9 {
				device_type = "vinc9";
				compatible = "allwinner,sunxi-vin-core";
				reg = <0x0 0x5831ffc 0x0 0x1004>;
				vinc9_csi_sel = <0x2>;
				vinc9_mipi_sel = <0xff>;
				vinc9_isp_sel = <0x0>;
				vinc9_isp_tx_ch = <0x0>;
				vinc9_tdm_rx_sel = <0x0>;
				vinc9_rear_sensor_sel = <0x0>;
				vinc9_front_sensor_sel = <0x0>;
				vinc9_sensor_list = <0x0>;
				device_id = <0x9>;
				work_mode = <0xff>;
				iommus = <0x24 0x1 0x1>;
				status = "disabled";
			};

			vinc@10 {
				device_type = "vinc10";
				compatible = "allwinner,sunxi-vin-core";
				reg = <0x0 0x5831ff8 0x0 0x1008>;
				vinc10_csi_sel = <0x2>;
				vinc10_mipi_sel = <0xff>;
				vinc10_isp_sel = <0x0>;
				vinc10_isp_tx_ch = <0x0>;
				vinc10_tdm_rx_sel = <0x0>;
				vinc10_rear_sensor_sel = <0x0>;
				vinc10_front_sensor_sel = <0x0>;
				vinc10_sensor_list = <0x0>;
				device_id = <0xa>;
				work_mode = <0xff>;
				iommus = <0x24 0x1 0x1>;
				status = "disabled";
			};

			vinc@11 {
				device_type = "vinc11";
				compatible = "allwinner,sunxi-vin-core";
				reg = <0x0 0x5831ff4 0x0 0x100c>;
				vinc11_csi_sel = <0x2>;
				vinc11_mipi_sel = <0xff>;
				vinc11_isp_sel = <0x0>;
				vinc11_isp_tx_ch = <0x0>;
				vinc11_tdm_rx_sel = <0x0>;
				vinc11_rear_sensor_sel = <0x0>;
				vinc11_front_sensor_sel = <0x0>;
				vinc11_sensor_list = <0x0>;
				device_id = <0xb>;
				work_mode = <0xff>;
				iommus = <0x24 0x1 0x1>;
				status = "disabled";
			};

			vinc@12 {
				device_type = "vinc12";
				compatible = "allwinner,sunxi-vin-core";
				reg = <0x0 0x5833000 0x0 0x1000>;
				interrupts = <0x0 0x62 0x4>;
				vinc12_csi_sel = <0x0>;
				vinc12_mipi_sel = <0x0>;
				vinc12_isp_sel = <0x0>;
				vinc12_isp_tx_ch = <0x0>;
				vinc12_tdm_rx_sel = <0x0>;
				vinc12_rear_sensor_sel = <0x0>;
				vinc12_front_sensor_sel = <0x0>;
				vinc12_sensor_list = <0x0>;
				device_id = <0xc>;
				work_mode = <0x1>;
				iommus = <0x24 0x1 0x1>;
				status = "okay";
			};

			vinc@13 {
				device_type = "vinc13";
				compatible = "allwinner,sunxi-vin-core";
				reg = <0x0 0x5832ffc 0x0 0x1004>;
				vinc13_csi_sel = <0x2>;
				vinc13_mipi_sel = <0xff>;
				vinc13_isp_sel = <0x0>;
				vinc13_isp_tx_ch = <0x0>;
				vinc13_tdm_rx_sel = <0x0>;
				vinc13_rear_sensor_sel = <0x0>;
				vinc13_front_sensor_sel = <0x0>;
				vinc13_sensor_list = <0x0>;
				device_id = <0xd>;
				work_mode = <0xff>;
				iommus = <0x24 0x1 0x1>;
				status = "disabled";
			};

			vinc@14 {
				device_type = "vinc14";
				compatible = "allwinner,sunxi-vin-core";
				reg = <0x0 0x5832ff8 0x0 0x1008>;
				vinc14_csi_sel = <0x2>;
				vinc14_mipi_sel = <0xff>;
				vinc14_isp_sel = <0x0>;
				vinc14_isp_tx_ch = <0x0>;
				vinc14_tdm_rx_sel = <0x0>;
				vinc14_rear_sensor_sel = <0x0>;
				vinc14_front_sensor_sel = <0x0>;
				vinc14_sensor_list = <0x0>;
				device_id = <0xe>;
				work_mode = <0xff>;
				iommus = <0x24 0x1 0x1>;
				status = "disabled";
			};

			vinc@15 {
				device_type = "vinc15";
				compatible = "allwinner,sunxi-vin-core";
				reg = <0x0 0x5832ff4 0x0 0x100c>;
				vinc15_csi_sel = <0x2>;
				vinc15_mipi_sel = <0xff>;
				vinc15_isp_sel = <0x0>;
				vinc15_isp_tx_ch = <0x0>;
				vinc15_tdm_rx_sel = <0x0>;
				vinc15_rear_sensor_sel = <0x0>;
				vinc15_front_sensor_sel = <0x0>;
				vinc15_sensor_list = <0x0>;
				device_id = <0xf>;
				work_mode = <0xff>;
				iommus = <0x24 0x1 0x1>;
				status = "disabled";
			};
		};

		e907_standby@0 {
			compatible = "allwinner,sunxi-e907-standby";
			firmware = "riscv.fex";
			mboxes = <0xb0 0x1>;
			mbox-names = "mbox-chan";
			power-domains = <0x25 0x0>;
			status = "okay";
		};

		wlan@0 {
			compatible = "allwinner,sunxi-wlan";
			pinctrl-0 = <0xb1>;
			pinctrl-names = "default";
			clock-names = "32k-fanout0";
			clocks = <0xb2>;
			wlan_busnum = <0x1>;
			wlan_power_num = <0x1>;
			wlan_power1 = "axp2101-dcdc1";
			wlan_io_regulator = "axp2101-dcdc1";
			wlan_power_voltage = <0x325aa0>;
			wlan_io_voltage = <0x325aa0>;
			wlan_regon = <0x26 0x7 0xf 0x1 0x1 0x2 0x0>;
			wlan_hostwake = <0x26 0x6 0x7 0xe 0x1 0x2 0x0>;
			chip_en;
			power_en;
			status = "okay";
			wakeup-source;
		};

		bt {
			compatible = "allwinner,sunxi-bt";
			clock-names = "32k-fanout0";
			clocks = <0xb2>;
			status = "disabled";
		};

		btlpm {
			compatible = "allwinner,sunxi-btlpm";
			uart_index = <0x2>;
			status = "disabled";
		};

		standby_param {
			vdd-cpu = <0x4>;
			vdd-sys = <0x4>;
			vcc-io = <0x1>;
			vdd-pll = <0x800>;
		};

		gpio_charger@0 {
			compatible = "gpio-charger";
			gpios = <0x26 0x7 0x3 0x0 0x1 0x1 0x1>;
			charger-type = "usb-sdp";
			status = "okay";
			linux,phandle = <0x7d>;
			phandle = <0x7d>;
		};
	};

	firmware {

		optee {
			compatible = "linaro,optee-tz";
			method = "smc";
		};
	};

	reserved-memory {
		#address-cells = <0x2>;
		#size-cells = <0x2>;
		ranges;

		optee_reserve {
			reg = <0x0 0x41980000 0x0 0x19000>;
			status = "okay";
		};

		riscv_memserve {
			reg = <0x0 0x48000000 0x0 0x400000>;
			no-map;
			linux,phandle = <0xbf>;
			phandle = <0xbf>;
		};

		vdev0buffer@47000000 {
			compatible = "shared-dma-pool";
			reg = <0x0 0x47000000 0x0 0x40000>;
			no-map;
			linux,phandle = <0xc0>;
			phandle = <0xc0>;
		};

		vdev0vring0@47040000 {
			reg = <0x0 0x47040000 0x0 0x20000>;
			no-map;
			linux,phandle = <0xc1>;
			phandle = <0xc1>;
		};

		vdev0vring1@47060000 {
			reg = <0x0 0x47060000 0x0 0x20000>;
			no-map;
			linux,phandle = <0xc2>;
			phandle = <0xc2>;
		};
	};

	aliases {
		pwm = "/soc@03000000/pwm@2000c00";
		pwm0 = "/soc@03000000/pwm0@2000c10";
		pwm1 = "/soc@03000000/pwm1@2000c11";
		pwm2 = "/soc@03000000/pwm2@2000c12";
		pwm3 = "/soc@03000000/pwm3@2000c13";
		pwm4 = "/soc@03000000/pwm4@2000c14";
		pwm5 = "/soc@03000000/pwm5@2000c15";
		pwm6 = "/soc@03000000/pwm6@2000c16";
		pwm7 = "/soc@03000000/pwm7@2000c17";
		pwm8 = "/soc@03000000/pwm8@2000c18";
		pwm9 = "/soc@03000000/pwm9@2000c19";
		pwm10 = "/soc@03000000/pwm10@2000c1a";
		pwm11 = "/soc@03000000/pwm11@2000c1b";
		serial0 = "/soc@03000000/uart@2500000";
		serial1 = "/soc@03000000/uart@2500400";
		serial2 = "/soc@03000000/uart@2500800";
		serial3 = "/soc@03000000/uart@2500c00";
		spi0 = "/soc@03000000/spi@04025000";
		spi1 = "/soc@03000000/spi@04026000";
		spi3 = "/soc@03000000/spi@04028000";
		spi5 = "/soc@03000000/spif@04f00000";
		disp = "/soc@03000000/disp@05000000";
		lcd0 = "/soc@03000000/lcd0@05461000";
		mmc0 = "/soc@03000000/sdmmc@4020000";
		mmc2 = "/soc@03000000/sdmmc@4022000";
		twi0 = "/soc@03000000/twi@0x02502000";
		twi1 = "/soc@03000000/twi@0x02502400";
		twi2 = "/soc@03000000/twi@0x02502800";
		twi3 = "/soc@03000000/twi@0x02502c00";
		twi4 = "/soc@03000000/twi@0x02503000";
		gmac0 = "/soc@03000000/eth@4500000";
		pmu0 = "/soc@03000000/twi@0x02503000/pmu@0";
		standby_param = "/soc@03000000/standby_param";
	};

	chosen {
		bootargs = "earlyprintk=sunxi-uart,0x02500000 loglevel=8 initcall_debug=0 console=ttyS0 init=/init";
		linux,initrd-start = <0x0 0x0>;
		linux,initrd-end = <0x0 0x0>;
	};

	cpus {
		enable-method = "allwinner,sun8iw21p1";
		#address-cells = <0x1>;
		#size-cells = <0x0>;

		cpu@0 {
			device_type = "cpu";
			compatible = "arm,cortex-a7";
			reg = <0x0>;
			enable-method = "psci";
			clocks = <0xb3>;
			clock-frequency = <0x3c14dc00>;
			clock-latency = <0x1e8480>;
			operating-points-v2 = <0xb4>;
			cpu-idle-states = <0xb5 0xb6 0xb7>;
			cooling-min-level = <0x5>;
			cooling-max-level = <0x0>;
			#cooling-cells = <0x2>;
			dynamic-power-coefficient = <0x8e>;
			cpu-supply = <0x30>;
			linux,phandle = <0xbd>;
			phandle = <0xbd>;
		};

		idle-states {
			entry-method = "arm,psci";

			cpu-sleep-0 {
				compatible = "arm,idle-state";
				arm,psci-suspend-param = <0x10000>;
				entry-latency-us = <0x2d>;
				exit-latency-us = <0x5a>;
				min-residency-us = <0xbb8>;
				local-timer-stop;
				linux,phandle = <0xb5>;
				phandle = <0xb5>;
			};

			cluster-sleep-0 {
				compatible = "arm,idle-state";
				arm,psci-suspend-param = <0x1010000>;
				entry-latency-us = <0x37>;
				exit-latency-us = <0x23a>;
				min-residency-us = <0x4268>;
				local-timer-stop;
				linux,phandle = <0xb6>;
				phandle = <0xb6>;
			};

			sys-sleep-0 {
				compatible = "arm,idle-state";
				arm,psci-suspend-param = <0x2010000>;
				entry-latency-us = <0xffffffff>;
				exit-latency-us = <0xffffffff>;
				min-residency-us = <0xffffffff>;
				local-timer-stop;
				linux,phandle = <0xb7>;
				phandle = <0xb7>;
			};
		};
	};

	opp_dvfs_table {
		cluster_num = <0x1>;
		opp_table_count = <0x1>;

		opp_l_table0 {
			compatible = "allwinner,opp_l_table0";
			opp_count = <0x6>;
			opp-shared;
			linux,phandle = <0xb4>;
			phandle = <0xb4>;

			opp00 {
				opp-hz = <0x0 0x18519600>;
				opp-microvolt = <0xdbba0>;
				axi-bus-divide-ratio = <0x3>;
				clock-latency-ns = <0x1e8480>;
			};

			opp01 {
				opp-hz = <0x0 0x23c34600>;
				opp-microvolt = <0xdbba0>;
				axi-bus-divide-ratio = <0x3>;
				clock-latency-ns = <0x1e8480>;
			};

			opp02 {
				opp-hz = <0x0 0x2aea5400>;
				opp-microvolt = <0xdbba0>;
				axi-bus-divide-ratio = <0x3>;
				clock-latency-ns = <0x1e8480>;
			};

			opp03 {
				opp-hz = <0x0 0x365c0400>;
				opp-microvolt = <0xdbba0>;
				axi-bus-divide-ratio = <0x3>;
				clock-latency-ns = <0x1e8480>;
			};

			opp04 {
				opp-hz = <0x0 0x3c14dc00>;
				opp-microvolt = <0xe7ef0>;
				axi-bus-divide-ratio = <0x3>;
				clock-latency-ns = <0x1e8480>;
			};

			opp05 {
				opp-hz = <0x0 0x41cdb400>;
				opp-microvolt = <0xf4240>;
				axi-bus-divide-ratio = <0x3>;
				clock-latency-ns = <0x1e8480>;
			};
		};
	};

	psci {
		compatible = "arm,psci-1.0";
		method = "smc";
	};

	ion {
		compatible = "allwinner,sunxi-ion";

		heap_sys_user@0 {
			compatible = "allwinner,sys_user";
			heap-name = "sys_user";
			heap-id = <0x0>;
			heap-base = <0x0>;
			heap-size = <0x0>;
			heap-type = "ion_system";
		};

		heap_cma@0 {
			compatible = "allwinner,cma";
			heap-name = "cma";
			heap-id = <0x4>;
			heap-base = <0x0>;
			heap-size = <0x0>;
			heap-type = "ion_cma";
		};
	};

	memory@40000000 {
		device_type = "memory";
		reg = <0x0 0x40000000 0x0 0x20000000>;
	};

	interrupt-controller@03020000 {
		compatible = "arm,cortex-a15-gic", "arm,cortex-a9-gic";
		#interrupt-cells = <0x3>;
		#address-cells = <0x0>;
		device_type = "gic";
		interrupt-controller;
		reg = <0x0 0x3021000 0x0 0x1000 0x0 0x3022000 0x0 0x2000 0x0 0x3024000 0x0 0x2000 0x0 0x3026000 0x0 0x2000>;
		interrupts = <0x1 0x9 0xf04>;
		interrupt-parent = <0xb8>;
		linux,phandle = <0xb8>;
		phandle = <0xb8>;
	};

	intc-nmi@07010320 {
		compatible = "allwinner,sun8i-nmi";
		interrupt-parent = <0xb8>;
		#interrupt-cells = <0x2>;
		#address-cells = <0x0>;
		interrupt-controller;
		reg = <0x0 0x7010320 0x0 0xc>;
		pad-control-v2 = <0x7090230>;
		pad-control-offset = <0x1e>;
		pad-control-en = <0x0>;
		interrupts = <0x0 0x88 0x4>;
		linux,phandle = <0x4b>;
		phandle = <0x4b>;
	};

	interrupt-controller@0 {
		compatible = "allwinner,sunxi-wakeupgen";
		interrupt-controller;
		#interrupt-cells = <0x3>;
		interrupt-parent = <0xb8>;
		linux,phandle = <0x1>;
		phandle = <0x1>;
	};

	sram_ctrl {
		device_type = "sram_ctrl";
		compatible = "allwinner,sram_ctrl";
		reg = <0x0 0x3000000 0x0 0x100>;
	};

	sunxi-sid@03006000 {
		compatible = "allwinner,sunxi-sid";
		device_type = "sid";
		reg = <0x0 0x3006000 0x0 0x200>;
	};

	sunxi-chipid@03006200 {
		compatible = "allwinner,sunxi-chipid";
		device_type = "chipid";
		reg = <0x0 0x3006200 0x0 0xc0>;
	};

	timer {
		compatible = "arm,armv7-timer";
		interrupts = <0x1 0xd 0x308 0x1 0xe 0x308 0x1 0xb 0x308 0x1 0xa 0x308>;
		clock-frequency = <0x16e3600>;
		arm,cpu-registers-not-fw-configured;
		interrupt-parent = <0xb8>;
		arm,no-tick-in-suspend;
	};

	ths@02009400 {
		compatible = "allwinner,sun8iw21p1-ths";
		reg = <0x0 0x2009400 0x0 0x400>;
		clocks = <0xb9>;
		clock-names = "bus";
		nvmem-cells = <0xba>;
		nvmem-cell-names = "calibration";
		#thermal-sensor-cells = <0x1>;
		linux,phandle = <0xbb>;
		phandle = <0xbb>;
	};

	thermal-zones {

		cpu_thermal_zone {
			polling-delay-passive = <0x1f4>;
			polling-delay = <0x3e8>;
			thermal-sensors = <0xbb 0x2>;
			sustainable-power = <0x44>;

			trips {

				trip-point@0 {
					temperature = <0x11170>;
					type = "passive";
					hysteresis = <0x0>;
				};

				trip-point@1 {
					temperature = <0x15f90>;
					type = "passive";
					hysteresis = <0x0>;
					linux,phandle = <0xbc>;
					phandle = <0xbc>;
				};

				cpu_crit@0 {
					temperature = <0x1adb0>;
					type = "critical";
					hysteresis = <0x0>;
				};
			};

			cooling-maps {

				map0 {
					trip = <0xbc>;
					cooling-device = <0xbd 0xffffffff 0xffffffff>;
					contribution = <0x400>;
				};
			};
		};

		npu_thermal_zone {
			polling-delay-passive = <0x0>;
			polling-delay = <0x0>;
			thermal-sensors = <0xbb 0x0>;
		};

		ve_thermal_zone {
			polling-delay-passive = <0x0>;
			polling-delay = <0x0>;
			thermal-sensors = <0xbb 0x1>;
		};
	};

	power-management@ff000000 {
		compatible = "allwinner,v853-pmu", "syscon", "simple-mfd";
		reg = <0x0 0x7001000 0x0 0x400>;

		power-controller {
			compatible = "allwinner,v853-power-controller";
			clocks = <0xbe>;
			clock-names = "ppu";
			#power-domain-cells = <0x1>;
			#address-cells = <0x1>;
			#size-cells = <0x0>;
			linux,phandle = <0x25>;
			phandle = <0x25>;

			pd_e907@0 {
				reg = <0x0>;
			};

			pd_npu@1 {
				reg = <0x1>;
			};

			pd_ve@2 {
				reg = <0x2>;
			};
		};
	};

	usb-vbus {
		compatible = "regulator-fixed";
		gpio = <0x26 0x7 0x2 0x1 0x2 0x0 0x1>;
		regulator-name = "usb-vbus";
		regulator-min-microvolt = <0x4c4b40>;
		regulator-max-microvolt = <0x4c4b40>;
		enable-active-high;
		linux,phandle = <0x81>;
		phandle = <0x81>;
	};

	e907_rproc@0 {
		compatible = "allwinner,sun8iw21p1-e907-rproc";
		clock-frequency = <0x23c34600>;
		memory-region = <0xbf 0xc0 0xc1 0xc2>;
		mboxes = <0xb0 0x0>;
		mbox-names = "mbox-chan";
		iommus = <0x24 0x5 0x1>;
		memory-mappings = <0x48000000 0x400000 0x48000000>;
		core-name = "sun8iw21p1-e907";
		firmware-name = "melis-elf";
		status = "okay";
		linux,phandle = <0xc3>;
		phandle = <0xc3>;
	};

	rpbuf_controller@0 {
		compatible = "allwinner,rpbuf-controller";
		remoteproc = <0xc3>;
		ctrl_id = <0x0>;
		iommus = <0x24 0x5 0x1>;
		status = "okay";
		linux,phandle = <0xc4>;
		phandle = <0xc4>;
	};

	rpbuf_sample@0 {
		compatible = "allwinner,rpbuf-sample";
		rpbuf = <0xc4>;
		status = "okay";
	};

	axp2101-parameter {
		select = "battery-model";
		linux,phandle = <0x4c>;
		phandle = <0x4c>;

		battery-model {
			parameter = <0x1f50000 0xfb0000fb 0x1e3201 0x1404d804 0x74fd580b 0xb3103ffb 0xc800be03 0x4e063f06 0x20ad30f 0x740f3109 0xe50eb90e 0xc004be04 0xbb09b40e 0xa00e9209 0x790e4c0e 0x2703fc03 0xd508bc0d 0x9c0d5506 0xb82e242e 0x2e242e24 0xc5987e66 0x4e44381a 0x120af600 0xf600f6 0xfb0000 0xfb0000fb 0xf600 0xf600f6 0xfb0000 0xfb0000fb 0xf600 0xf600f6>;
		};
	};

	tp9953_detect {
		gpio_power = <0x26 0x4 0xd 0x1 0x0 0x1 0x0>;
		gpio_detect = <0x26 0x4 0xe 0x1 0x0 0x1 0x0>;
		gpio_reverse = <0x26 0x4 0xc 0x1 0x0 0x1 0x1>;
	};
};
